AUTOSAR XML (schema 3.1.2)
package /Components/SWC_EBStub
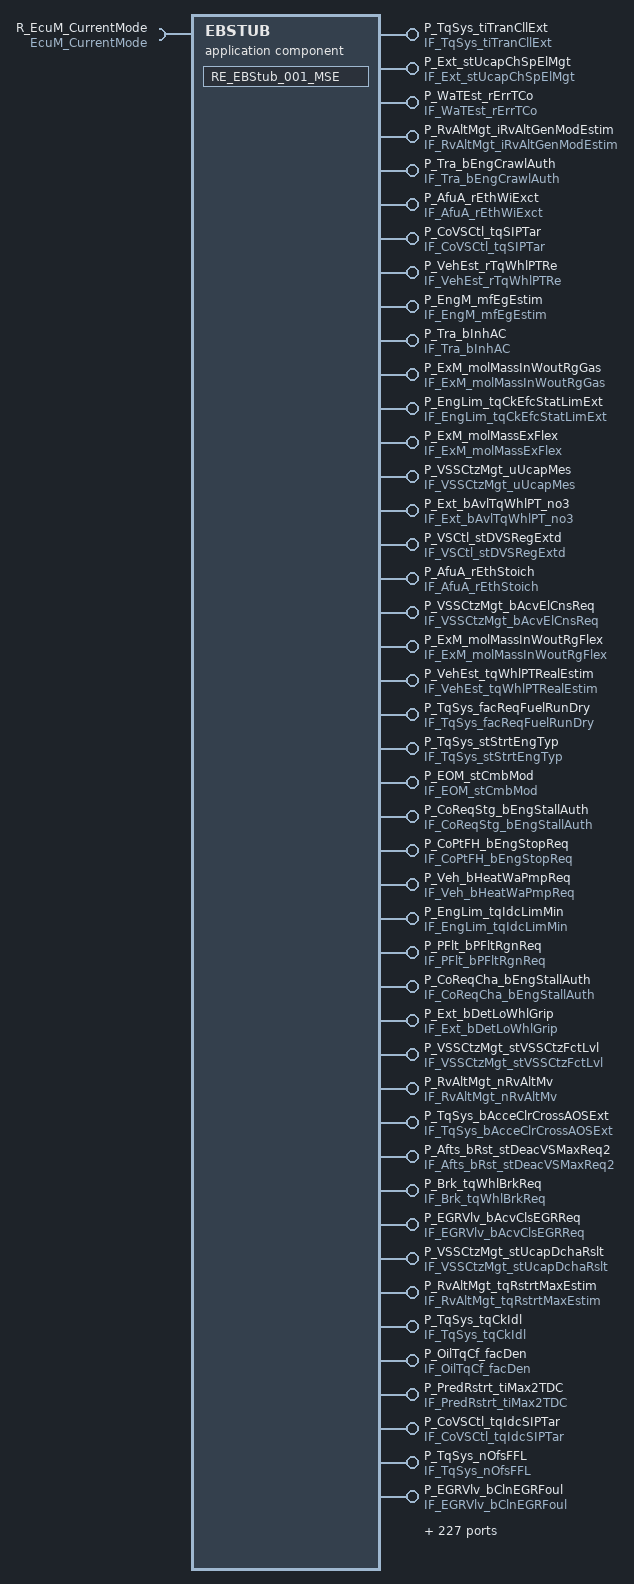
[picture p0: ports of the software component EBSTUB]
  application software component type EBSTUB
    require port R_EcuM_CurrentMode: required-interface=EcuM_CurrentMode
    271 x provide port:
      P_TqSys_tiTranCllExt: unqueued-sender-com-spec{data-element=TqSys_tiTranCllExt, can-invalidate=false, init-value=ConstantValue}, provided-interface=IF_TqSys_tiTranCllExt
      P_Ext_stUcapChSpElMgt: unqueued-sender-com-spec{data-element=Ext_stUcapChSpElMgt, can-invalidate=false, init-value=ConstantValue1}, provided-interface=IF_Ext_stUcapChSpElMgt
      P_WaTEst_rErrTCo: unqueued-sender-com-spec{data-element=WaTEst_rErrTCo, can-invalidate=false, init-value=ConstantValue3}, provided-interface=IF_WaTEst_rErrTCo
      P_RvAltMgt_iRvAltGenModEstim: unqueued-sender-com-spec{data-element=RvAltMgt_iRvAltGenModEstim, can-invalidate=false, init-value=ConstantValue5}, provided-interface=IF_RvAltMgt_iRvAltGenModEstim
      P_Tra_bEngCrawlAuth: unqueued-sender-com-spec{data-element=Tra_bEngCrawlAuth, can-invalidate=false, init-value=ConstantValue7}, provided-interface=IF_Tra_bEngCrawlAuth
      P_AfuA_rEthWiExct: unqueued-sender-com-spec{data-element=AfuA_rEthWiExct, can-invalidate=false, init-value=ConstantValue9}, provided-interface=IF_AfuA_rEthWiExct
      P_CoVSCtl_tqSIPTar: unqueued-sender-com-spec{data-element=CoVSCtl_tqSIPTar, can-invalidate=false, init-value=ConstantValue11}, provided-interface=IF_CoVSCtl_tqSIPTar
      P_VehEst_rTqWhlPTRe: unqueued-sender-com-spec{data-element=VehEst_rTqWhlPTRe, can-invalidate=false, init-value=ConstantValue13}, provided-interface=IF_VehEst_rTqWhlPTRe
      P_EngM_mfEgEstim: unqueued-sender-com-spec{data-element=EngM_mfEgEstim, can-invalidate=false, init-value=ConstantValue15}, provided-interface=IF_EngM_mfEgEstim
      P_Tra_bInhAC: unqueued-sender-com-spec{data-element=Tra_bInhAC, can-invalidate=false, init-value=ConstantValue17}, provided-interface=IF_Tra_bInhAC
      P_ExM_molMassInWoutRgGas: unqueued-sender-com-spec{data-element=ExM_molMassInWoutRgGas, can-invalidate=false, init-value=ConstantValue19}, provided-interface=IF_ExM_molMassInWoutRgGas
      P_EngLim_tqCkEfcStatLimExt: unqueued-sender-com-spec{data-element=EngLim_tqCkEfcStatLimExt, can-invalidate=false, init-value=ConstantValue21}, provided-interface=IF_EngLim_tqCkEfcStatLimExt
      P_ExM_molMassExFlex: unqueued-sender-com-spec{data-element=ExM_molMassExFlex, can-invalidate=false, init-value=ConstantValue23}, provided-interface=IF_ExM_molMassExFlex
      P_VSSCtzMgt_uUcapMes: unqueued-sender-com-spec{data-element=VSSCtzMgt_uUcapMes, can-invalidate=false, init-value=ConstantValue25}, provided-interface=IF_VSSCtzMgt_uUcapMes
      P_Ext_bAvlTqWhlPT_no3: unqueued-sender-com-spec{data-element=Ext_bAvlTqWhlPT_no3, can-invalidate=false, init-value=ConstantValue27}, provided-interface=IF_Ext_bAvlTqWhlPT_no3
      P_VSCtl_stDVSRegExtd: unqueued-sender-com-spec{data-element=VSCtl_stDVSRegExtd, can-invalidate=false, init-value=ConstantValue29}, provided-interface=IF_VSCtl_stDVSRegExtd
      P_AfuA_rEthStoich: unqueued-sender-com-spec{data-element=AfuA_rEthStoich, can-invalidate=false, init-value=ConstantValue31}, provided-interface=IF_AfuA_rEthStoich
      P_VSSCtzMgt_bAcvElCnsReq: unqueued-sender-com-spec{data-element=VSSCtzMgt_bAcvElCnsReq, can-invalidate=false, init-value=ConstantValue33}, provided-interface=IF_VSSCtzMgt_bAcvElCnsReq
      P_ExM_molMassInWoutRgFlex: unqueued-sender-com-spec{data-element=ExM_molMassInWoutRgFlex, can-invalidate=false, init-value=ConstantValue35}, provided-interface=IF_ExM_molMassInWoutRgFlex
      P_VehEst_tqWhlPTRealEstim: unqueued-sender-com-spec{data-element=VehEst_tqWhlPTRealEstim, can-invalidate=false, init-value=ConstantValue37}, provided-interface=IF_VehEst_tqWhlPTRealEstim
      P_TqSys_facReqFuelRunDry: unqueued-sender-com-spec{data-element=TqSys_facReqFuelRunDry, can-invalidate=false, init-value=ConstantValue39}, provided-interface=IF_TqSys_facReqFuelRunDry
      P_TqSys_stStrtEngTyp: unqueued-sender-com-spec{data-element=TqSys_stStrtEngTyp, can-invalidate=false, init-value=ConstantValue41}, provided-interface=IF_TqSys_stStrtEngTyp
      P_EOM_stCmbMod: unqueued-sender-com-spec{data-element=EOM_stCmbMod, can-invalidate=false, init-value=ConstantValue43}, provided-interface=IF_EOM_stCmbMod
      P_CoReqStg_bEngStallAuth: unqueued-sender-com-spec{data-element=CoReqStg_bEngStallAuth, can-invalidate=false, init-value=ConstantValue45}, provided-interface=IF_CoReqStg_bEngStallAuth
      P_CoPtFH_bEngStopReq: unqueued-sender-com-spec{data-element=CoPtFH_bEngStopReq, can-invalidate=false, init-value=ConstantValue47}, provided-interface=IF_CoPtFH_bEngStopReq
      P_Veh_bHeatWaPmpReq: unqueued-sender-com-spec{data-element=Veh_bHeatWaPmpReq, can-invalidate=false, init-value=ConstantValue49}, provided-interface=IF_Veh_bHeatWaPmpReq
      P_EngLim_tqIdcLimMin: unqueued-sender-com-spec{data-element=EngLim_tqIdcLimMin, can-invalidate=false, init-value=ConstantValue51}, provided-interface=IF_EngLim_tqIdcLimMin
      P_PFlt_bPFltRgnReq: unqueued-sender-com-spec{data-element=PFlt_bPFltRgnReq, can-invalidate=false, init-value=ConstantValue53}, provided-interface=IF_PFlt_bPFltRgnReq
      P_CoReqCha_bEngStallAuth: unqueued-sender-com-spec{data-element=CoReqCha_bEngStallAuth, can-invalidate=false, init-value=ConstantValue55}, provided-interface=IF_CoReqCha_bEngStallAuth
      P_Ext_bDetLoWhlGrip: unqueued-sender-com-spec{data-element=Ext_bDetLoWhlGrip, can-invalidate=false, init-value=ConstantValue57}, provided-interface=IF_Ext_bDetLoWhlGrip
      P_VSSCtzMgt_stVSSCtzFctLvl: unqueued-sender-com-spec{data-element=VSSCtzMgt_stVSSCtzFctLvl, can-invalidate=false, init-value=ConstantValue59}, provided-interface=IF_VSSCtzMgt_stVSSCtzFctLvl
      P_RvAltMgt_nRvAltMv: unqueued-sender-com-spec{data-element=RvAltMgt_nRvAltMv, can-invalidate=false, init-value=ConstantValue61}, provided-interface=IF_RvAltMgt_nRvAltMv
      P_TqSys_bAcceClrCrossAOSExt: unqueued-sender-com-spec{data-element=TqSys_bAcceClrCrossAOSExt, can-invalidate=false, init-value=ConstantValue63}, provided-interface=IF_TqSys_bAcceClrCrossAOSExt
      P_Afts_bRst_stDeacVSMaxReq2: unqueued-sender-com-spec{data-element=Afts_bRst_stDeacVSMaxReq2, can-invalidate=false, init-value=ConstantValue65}, provided-interface=IF_Afts_bRst_stDeacVSMaxReq2
      P_Brk_tqWhlBrkReq: unqueued-sender-com-spec{data-element=Brk_tqWhlBrkReq, can-invalidate=false, init-value=ConstantValue67}, provided-interface=IF_Brk_tqWhlBrkReq
      P_EGRVlv_bAcvClsEGRReq: unqueued-sender-com-spec{data-element=EGRVlv_bAcvClsEGRReq, can-invalidate=false, init-value=ConstantValue69}, provided-interface=IF_EGRVlv_bAcvClsEGRReq
      P_VSSCtzMgt_stUcapDchaRslt: unqueued-sender-com-spec{data-element=VSSCtzMgt_stUcapDchaRslt, can-invalidate=false, init-value=ConstantValue71}, provided-interface=IF_VSSCtzMgt_stUcapDchaRslt
      P_RvAltMgt_tqRstrtMaxEstim: unqueued-sender-com-spec{data-element=RvAltMgt_tqRstrtMaxEstim, can-invalidate=false, init-value=ConstantValue73}, provided-interface=IF_RvAltMgt_tqRstrtMaxEstim
      P_TqSys_tqCkIdl: unqueued-sender-com-spec{data-element=TqSys_tqCkIdl, can-invalidate=false, init-value=ConstantValue75}, provided-interface=IF_TqSys_tqCkIdl
      P_OilTqCf_facDen: unqueued-sender-com-spec{data-element=OilTqCf_facDen, can-invalidate=false, init-value=ConstantValue77}, provided-interface=IF_OilTqCf_facDen
      P_PredRstrt_tiMax2TDC: unqueued-sender-com-spec{data-element=PredRstrt_tiMax2TDC, can-invalidate=false, init-value=ConstantValue79}, provided-interface=IF_PredRstrt_tiMax2TDC
      P_CoVSCtl_tqIdcSIPTar: unqueued-sender-com-spec{data-element=CoVSCtl_tqIdcSIPTar, can-invalidate=false, init-value=ConstantValue81}, provided-interface=IF_CoVSCtl_tqIdcSIPTar
      P_TqSys_nOfsFFL: unqueued-sender-com-spec{data-element=TqSys_nOfsFFL, can-invalidate=false, init-value=ConstantValue83}, provided-interface=IF_TqSys_nOfsFFL
      P_EGRVlv_bClnEGRFoul: unqueued-sender-com-spec{data-element=EGRVlv_bClnEGRFoul, can-invalidate=false, init-value=ConstantValue85}, provided-interface=IF_EGRVlv_bClnEGRFoul
      P_TqLimUH_bAcvUnBlsEng: unqueued-sender-com-spec{data-element=TqLimUH_bAcvUnBlsEng, can-invalidate=false, init-value=ConstantValue87}, provided-interface=IF_TqLimUH_bAcvUnBlsEng
      P_PtLim_tqWhlPTMaxCtla: unqueued-sender-com-spec{data-element=PtLim_tqWhlPTMaxCtla, can-invalidate=false, init-value=ConstantValue89}, provided-interface=IF_PtLim_tqWhlPTMaxCtla
      P_TqSys_bIdlAcv: unqueued-sender-com-spec{data-element=TqSys_bIdlAcv, can-invalidate=false, init-value=ConstantValue91}, provided-interface=IF_TqSys_bIdlAcv
      P_ExM_tExFlexOfs: unqueued-sender-com-spec{data-element=ExM_tExFlexOfs, can-invalidate=false, init-value=ConstantValue93}, provided-interface=IF_ExM_tExFlexOfs
      P_CoReqVeh_bEngASERstrtReq: unqueued-sender-com-spec{data-element=CoReqVeh_bEngASERstrtReq, can-invalidate=false, init-value=ConstantValue95}, provided-interface=IF_CoReqVeh_bEngASERstrtReq
      P_TqEst_tqIdcStrt: unqueued-sender-com-spec{data-element=TqEst_tqIdcStrt, can-invalidate=false, init-value=ConstantValue97}, provided-interface=IF_TqEst_tqIdcStrt
      P_ExM_tExGas: unqueued-sender-com-spec{data-element=ExM_tExGas, can-invalidate=false, init-value=ConstantValue99}, provided-interface=IF_ExM_tExGas
      P_CoPt_tqEfcAirCordLimExtTqGBx: unqueued-sender-com-spec{data-element=CoPt_tqEfcAirCordLimExtTqGBx, can-invalidate=false, init-value=ConstantValue101}, provided-interface=IF_CoPt_tqEfcAirCordLimExtTqGBx
      P_TqDem_tqWhlPTPreCoVSCMaxReq: unqueued-sender-com-spec{data-element=TqDem_tqWhlPTPreCoVSCMaxReq, can-invalidate=false, init-value=ConstantValue103}, provided-interface=IF_TqDem_tqWhlPTPreCoVSCMaxReq
      P_Ext_tVSS: unqueued-sender-com-spec{data-element=Ext_tVSS, can-invalidate=false, init-value=ConstantValue105}, provided-interface=IF_Ext_tVSS
      P_EGRVlv_rOp: unqueued-sender-com-spec{data-element=EGRVlv_rOp, can-invalidate=false, init-value=ConstantValue107}, provided-interface=IF_EGRVlv_rOp
      P_CoCha_bInhEGRExt: unqueued-sender-com-spec{data-element=CoCha_bInhEGRExt, can-invalidate=false, init-value=ConstantValue109}, provided-interface=IF_CoCha_bInhEGRExt
      P_RvAltMgt_tRvAltStatEstim: unqueued-sender-com-spec{data-element=RvAltMgt_tRvAltStatEstim, can-invalidate=false, init-value=ConstantValue111}, provided-interface=IF_RvAltMgt_tRvAltStatEstim
      P_EngM_tUsTrbEstimFil: unqueued-sender-com-spec{data-element=EngM_tUsTrbEstimFil, can-invalidate=false, init-value=ConstantValue113}, provided-interface=IF_EngM_tUsTrbEstimFil
      P_Afts_bVSSCtzActrTestCmd: unqueued-sender-com-spec{data-element=Afts_bVSSCtzActrTestCmd, can-invalidate=false, init-value=ConstantValue115}, provided-interface=IF_Afts_bVSSCtzActrTestCmd
      P_Ext_stPwrLimCf: unqueued-sender-com-spec{data-element=Ext_stPwrLimCf, can-invalidate=false, init-value=ConstantValue117}, provided-interface=IF_Ext_stPwrLimCf
      P_ExM_molMassExGas: unqueued-sender-com-spec{data-element=ExM_molMassExGas, can-invalidate=false, init-value=ConstantValue119}, provided-interface=IF_ExM_molMassExGas
      P_TqSys_tqCkEfcAirFilExt: unqueued-sender-com-spec{data-element=TqSys_tqCkEfcAirFilExt, can-invalidate=false, init-value=ConstantValue121}, provided-interface=IF_TqSys_tqCkEfcAirFilExt
      P_Afts_bRstTrbCaseDmgReq: unqueued-sender-com-spec{data-element=Afts_bRstTrbCaseDmgReq, can-invalidate=false, init-value=ConstantValue123}, provided-interface=IF_Afts_bRstTrbCaseDmgReq
      P_SftyMgt_bDeacIrvVSLim: unqueued-sender-com-spec{data-element=SftyMgt_bDeacIrvVSLim, can-invalidate=false, init-value=ConstantValue125}, provided-interface=IF_SftyMgt_bDeacIrvVSLim
      P_IgSys_agIgCmbModOfsMinThermo: unqueued-sender-com-spec{data-element=IgSys_agIgCmbModOfsMinThermo, can-invalidate=false, init-value=ConstantValue127}, provided-interface=IF_IgSys_agIgCmbModOfsMinThermo
      P_PtLim_tqWhlPTMinNotCtla: unqueued-sender-com-spec{data-element=PtLim_tqWhlPTMinNotCtla, can-invalidate=false, init-value=ConstantValue129}, provided-interface=IF_PtLim_tqWhlPTMinNotCtla
      P_Stg_tSysStrWhl: unqueued-sender-com-spec{data-element=Stg_tSysStrWhl, can-invalidate=false, init-value=ConstantValue131}, provided-interface=IF_Stg_tSysStrWhl
      P_CoEmSTT_bEngASERstrtReq: unqueued-sender-com-spec{data-element=CoEmSTT_bEngASERstrtReq, can-invalidate=false, init-value=ConstantValue133}, provided-interface=IF_CoEmSTT_bEngASERstrtReq
      P_GlwCtl_bEngRunAuth: unqueued-sender-com-spec{data-element=GlwCtl_bEngRunAuth, can-invalidate=false, init-value=ConstantValue135}, provided-interface=IF_GlwCtl_bEngRunAuth
      P_CoPtUH_bEngAsiReqExt: unqueued-sender-com-spec{data-element=CoPtUH_bEngAsiReqExt, can-invalidate=false, init-value=ConstantValue137}, provided-interface=IF_CoPtUH_bEngAsiReqExt
      P_ExM_prm_facFlex: unqueued-sender-com-spec{data-element=ExM_prm_facFlex, can-invalidate=false, init-value=ArrayConstantValue}, provided-interface=IF_ExM_prm_facFlex
      P_CoEmSTT_bAuthBoost: unqueued-sender-com-spec{data-element=CoEmSTT_bAuthBoost, can-invalidate=false, init-value=ConstantValue139}, provided-interface=IF_CoEmSTT_bAuthBoost
      P_ExM_prm_facGas: unqueued-sender-com-spec{data-element=ExM_prm_facGas, can-invalidate=false, init-value=ArrayConstantValue141}, provided-interface=IF_ExM_prm_facGas
      P_Afts_bRstCylHdDmgReq: unqueued-sender-com-spec{data-element=Afts_bRstCylHdDmgReq, can-invalidate=false, init-value=ConstantValue143}, provided-interface=IF_Afts_bRstCylHdDmgReq
      P_ExM_cppExFlex: unqueued-sender-com-spec{data-element=ExM_cppExFlex, can-invalidate=false, init-value=ConstantValue145}, provided-interface=IF_ExM_cppExFlex
      P_VSCtl_stVSReg: unqueued-sender-com-spec{data-element=VSCtl_stVSReg, can-invalidate=false, init-value=ConstantValue147}, provided-interface=IF_VSCtl_stVSReg
      P_CoSync_bAgEsCfm: unqueued-sender-com-spec{data-element=CoSync_bAgEsCfm, can-invalidate=false, init-value=ConstantValue149}, provided-interface=IF_CoSync_bAgEsCfm
      P_RvAltMgt_bStopStrtWarn: unqueued-sender-com-spec{data-element=RvAltMgt_bStopStrtWarn, can-invalidate=false, init-value=ConstantValue151}, provided-interface=IF_RvAltMgt_bStopStrtWarn
      P_EOM_idxBas2InjCur: unqueued-sender-com-spec{data-element=EOM_idxBas2InjCur, can-invalidate=false, init-value=ConstantValue153}, provided-interface=IF_EOM_idxBas2InjCur
      P_TqSys_noCylCutAuthExt: unqueued-sender-com-spec{data-element=TqSys_noCylCutAuthExt, can-invalidate=false, init-value=ConstantValue155}, provided-interface=IF_TqSys_noCylCutAuthExt
      P_CoReqDmpr_stEngStopAuth: unqueued-sender-com-spec{data-element=CoReqDmpr_stEngStopAuth, can-invalidate=false, init-value=ConstantValue157}, provided-interface=IF_CoReqDmpr_stEngStopAuth
      P_VSCtl_stVSLim: unqueued-sender-com-spec{data-element=VSCtl_stVSLim, can-invalidate=false, init-value=ConstantValue159}, provided-interface=IF_VSCtl_stVSLim
      P_VehEst_bORng_nPT: unqueued-sender-com-spec{data-element=VehEst_bORng_nPT, can-invalidate=false, init-value=ConstantValue161}, provided-interface=IF_VehEst_bORng_nPT
      P_IgSys_agIgOptmFlex: unqueued-sender-com-spec{data-element=IgSys_agIgOptmFlex, can-invalidate=false, init-value=ConstantValue163}, provided-interface=IF_IgSys_agIgOptmFlex
      P_Afts_bRst_stDeacVSLimReq2: unqueued-sender-com-spec{data-element=Afts_bRst_stDeacVSLimReq2, can-invalidate=false, init-value=ConstantValue165}, provided-interface=IF_Afts_bRst_stDeacVSLimReq2
      P_Ext_bAvlTqWhlPT_no2: unqueued-sender-com-spec{data-element=Ext_bAvlTqWhlPT_no2, can-invalidate=false, init-value=ConstantValue167}, provided-interface=IF_Ext_bAvlTqWhlPT_no2
      P_CoPtFH_stPwt: unqueued-sender-com-spec{data-element=CoPtFH_stPwt, can-invalidate=false, init-value=ConstantValue169}, provided-interface=IF_CoPtFH_stPwt
      P_TqSys_bInhBrio: unqueued-sender-com-spec{data-element=TqSys_bInhBrio, can-invalidate=false, init-value=ConstantValue171}, provided-interface=IF_TqSys_bInhBrio
      P_AfuA_rEthWoutExct: unqueued-sender-com-spec{data-element=AfuA_rEthWoutExct, can-invalidate=false, init-value=ConstantValue173}, provided-interface=IF_AfuA_rEthWoutExct
      P_ExM_facIgCorGas: unqueued-sender-com-spec{data-element=ExM_facIgCorGas, can-invalidate=false, init-value=ConstantValue175}, provided-interface=IF_ExM_facIgCorGas
      P_Ext_bAvlTqWhlPT_no1: unqueued-sender-com-spec{data-element=Ext_bAvlTqWhlPT_no1, can-invalidate=false, init-value=ConstantValue177}, provided-interface=IF_Ext_bAvlTqWhlPT_no1
      P_Afts_bRst_stDeacVSRegReq2: unqueued-sender-com-spec{data-element=Afts_bRst_stDeacVSRegReq2, can-invalidate=false, init-value=ConstantValue179}, provided-interface=IF_Afts_bRst_stDeacVSRegReq2
      P_CoPt_nTarIdlCVC: unqueued-sender-com-spec{data-element=CoPt_nTarIdlCVC, can-invalidate=false, init-value=ConstantValue181}, provided-interface=IF_CoPt_nTarIdlCVC
      P_EngReqH_bEngStallAuth: unqueued-sender-com-spec{data-element=EngReqH_bEngStallAuth, can-invalidate=false, init-value=ConstantValue183}, provided-interface=IF_EngReqH_bEngStallAuth
      P_TqCmp_bOpFSFReq_tAir: unqueued-sender-com-spec{data-element=TqCmp_bOpFSFReq_tAir, can-invalidate=false, init-value=ConstantValue185}, provided-interface=IF_TqCmp_bOpFSFReq_tAir
      P_IgSys_agIgMinThermoGas: unqueued-sender-com-spec{data-element=IgSys_agIgMinThermoGas, can-invalidate=false, init-value=ConstantValue187}, provided-interface=IF_IgSys_agIgMinThermoGas
      P_TqSys_bDeceDetAOSExt: unqueued-sender-com-spec{data-element=TqSys_bDeceDetAOSExt, can-invalidate=false, init-value=ConstantValue189}, provided-interface=IF_TqSys_bDeceDetAOSExt
      P_TqSys_nOfsLauchIdlTakeOff: unqueued-sender-com-spec{data-element=TqSys_nOfsLauchIdlTakeOff, can-invalidate=false, init-value=ConstantValue191}, provided-interface=IF_TqSys_nOfsLauchIdlTakeOff
      P_Brk_bBrkAuto: unqueued-sender-com-spec{data-element=Brk_bBrkAuto, can-invalidate=false, init-value=ConstantValue193}, provided-interface=IF_Brk_bBrkAuto
      P_Ext_bEspVehVld: unqueued-sender-com-spec{data-element=Ext_bEspVehVld, can-invalidate=false, init-value=ConstantValue195}, provided-interface=IF_Ext_bEspVehVld
      P_FARSp_rDeltaMixtStiTWCSp: unqueued-sender-com-spec{data-element=FARSp_rDeltaMixtStiTWCSp, can-invalidate=false, init-value=ConstantValue197}, provided-interface=IF_FARSp_rDeltaMixtStiTWCSp
      P_RvAltMgt_uRvAltMes: unqueued-sender-com-spec{data-element=RvAltMgt_uRvAltMes, can-invalidate=false, init-value=ConstantValue199}, provided-interface=IF_RvAltMgt_uRvAltMes
      P_CoReqDamp_bEngStallAuth: unqueued-sender-com-spec{data-element=CoReqDamp_bEngStallAuth, can-invalidate=false, init-value=ConstantValue201}, provided-interface=IF_CoReqDamp_bEngStallAuth
      P_ElSysCo_rSpdFanReq: unqueued-sender-com-spec{data-element=ElSysCo_rSpdFanReq, can-invalidate=false, init-value=ConstantValue203}, provided-interface=IF_ElSysCo_rSpdFanReq
      P_CoPt_bDeacCllExt: unqueued-sender-com-spec{data-element=CoPt_bDeacCllExt, can-invalidate=false, init-value=ConstantValue205}, provided-interface=IF_CoPt_bDeacCllExt
      P_CoVlv_rOpRadCoVlvMes: unqueued-sender-com-spec{data-element=CoVlv_rOpRadCoVlvMes, can-invalidate=false, init-value=ConstantValue207}, provided-interface=IF_CoVlv_rOpRadCoVlvMes
      P_EOM_stEngModReq: unqueued-sender-com-spec{data-element=EOM_stEngModReq, can-invalidate=false, init-value=ConstantValue209}, provided-interface=IF_EOM_stEngModReq
      P_CoCha_tqEfcAirReqExt: unqueued-sender-com-spec{data-element=CoCha_tqEfcAirReqExt, can-invalidate=false, init-value=ConstantValue211}, provided-interface=IF_CoCha_tqEfcAirReqExt
      P_Tra_stVehDirEstim: unqueued-sender-com-spec{data-element=Tra_stVehDirEstim, can-invalidate=false, init-value=ConstantValue213}, provided-interface=IF_Tra_stVehDirEstim
      P_RvAltMgt_stRvAltRstrtFbCmd: unqueued-sender-com-spec{data-element=RvAltMgt_stRvAltRstrtFbCmd, can-invalidate=false, init-value=ConstantValue215}, provided-interface=IF_RvAltMgt_stRvAltRstrtFbCmd
      P_Ext_bAvrFrntWhlVld: unqueued-sender-com-spec{data-element=Ext_bAvrFrntWhlVld, can-invalidate=false, init-value=ConstantValue217}, provided-interface=IF_Ext_bAvrFrntWhlVld
      P_EngLim_tqIdcSmkLim: unqueued-sender-com-spec{data-element=EngLim_tqIdcSmkLim, can-invalidate=false, init-value=ConstantValue219}, provided-interface=IF_EngLim_tqIdcSmkLim
      P_OilTqCf_bPresOilReqCf: unqueued-sender-com-spec{data-element=OilTqCf_bPresOilReqCf, can-invalidate=false, init-value=ConstantValue221}, provided-interface=IF_OilTqCf_bPresOilReqCf
      P_Afts_bUcapChgIdc: unqueued-sender-com-spec{data-element=Afts_bUcapChgIdc, can-invalidate=false, init-value=ConstantValue223}, provided-interface=IF_Afts_bUcapChgIdc
      P_Ext_bFrntLeftWhlVehVld: unqueued-sender-com-spec{data-element=Ext_bFrntLeftWhlVehVld, can-invalidate=false, init-value=ConstantValue225}, provided-interface=IF_Ext_bFrntLeftWhlVehVld
      P_EngM_dstInVlvClrCor: unqueued-sender-com-spec{data-element=EngM_dstInVlvClrCor, can-invalidate=false, init-value=ConstantValue227}, provided-interface=IF_EngM_dstInVlvClrCor
      P_Afts_bRstExMnfDmgReq: unqueued-sender-com-spec{data-element=Afts_bRstExMnfDmgReq, can-invalidate=false, init-value=ConstantValue229}, provided-interface=IF_Afts_bRstExMnfDmgReq
      P_EngM_facCorOfsEfc: unqueued-sender-com-spec{data-element=EngM_facCorOfsEfc, can-invalidate=false, init-value=ConstantValue231}, provided-interface=IF_EngM_facCorOfsEfc
      P_Tra_bSpdVehLoDet: unqueued-sender-com-spec{data-element=Tra_bSpdVehLoDet, can-invalidate=false, init-value=ConstantValue233}, provided-interface=IF_Tra_bSpdVehLoDet
      P_IgSys_prm_facFlex: unqueued-sender-com-spec{data-element=IgSys_prm_facFlex, can-invalidate=false, init-value=ArrayConstantValue235}, provided-interface=IF_IgSys_prm_facFlex
      P_EOM_idxBas1InjCur: unqueued-sender-com-spec{data-element=EOM_idxBas1InjCur, can-invalidate=false, init-value=ConstantValue237}, provided-interface=IF_EOM_idxBas1InjCur
      P_InjSP_mfFuPoI1Req: unqueued-sender-com-spec{data-element=InjSP_mfFuPoI1Req, can-invalidate=false, init-value=ConstantValue239}, provided-interface=IF_InjSP_mfFuPoI1Req
      P_Ext_bTqAltEstimElSys: unqueued-sender-com-spec{data-element=Ext_bTqAltEstimElSys, can-invalidate=false, init-value=ConstantValue241}, provided-interface=IF_Ext_bTqAltEstimElSys
      P_CoPt_bAcvTqNCordBuf: unqueued-sender-com-spec{data-element=CoPt_bAcvTqNCordBuf, can-invalidate=false, init-value=ConstantValue243}, provided-interface=IF_CoPt_bAcvTqNCordBuf
      P_Ext_stSpdFanPFltReq: unqueued-sender-com-spec{data-element=Ext_stSpdFanPFltReq, can-invalidate=false, init-value=ConstantValue245}, provided-interface=IF_Ext_stSpdFanPFltReq
      P_VehEst_bCtlTqWhlPT: unqueued-sender-com-spec{data-element=VehEst_bCtlTqWhlPT, can-invalidate=false, init-value=ConstantValue247}, provided-interface=IF_VehEst_bCtlTqWhlPT
      P_IgSys_rTarStatIgSpEff: unqueued-sender-com-spec{data-element=IgSys_rTarStatIgSpEff, can-invalidate=false, init-value=ConstantValue249}, provided-interface=IF_IgSys_rTarStatIgSpEff
      P_EngLim_tqIdcEngLim: unqueued-sender-com-spec{data-element=EngLim_tqIdcEngLim, can-invalidate=false, init-value=ConstantValue251}, provided-interface=IF_EngLim_tqIdcEngLim
      P_TqSys_tqCkEfcFilExt: unqueued-sender-com-spec{data-element=TqSys_tqCkEfcFilExt, can-invalidate=false, init-value=ConstantValue253}, provided-interface=IF_TqSys_tqCkEfcFilExt
      P_PARM_bEngRstrtAutnAvl: unqueued-sender-com-spec{data-element=PARM_bEngRstrtAutnAvl, can-invalidate=false, init-value=ConstantValue255}, provided-interface=IF_PARM_bEngRstrtAutnAvl
      P_TqSys_stDrivFilPhaExt: unqueued-sender-com-spec{data-element=TqSys_stDrivFilPhaExt, can-invalidate=false, init-value=ConstantValue257}, provided-interface=IF_TqSys_stDrivFilPhaExt
      P_EGRVlv_rOpEGRReq: unqueued-sender-com-spec{data-element=EGRVlv_rOpEGRReq, can-invalidate=false, init-value=ConstantValue259}, provided-interface=IF_EGRVlv_rOpEGRReq
      P_VSSCtzMgt_tUcapMes: unqueued-sender-com-spec{data-element=VSSCtzMgt_tUcapMes, can-invalidate=false, init-value=ConstantValue261}, provided-interface=IF_VSSCtzMgt_tUcapMes
      P_VSCtl_rCtlTqWhlPTPotDVSReg: unqueued-sender-com-spec{data-element=VSCtl_rCtlTqWhlPTPotDVSReg, can-invalidate=false, init-value=ConstantValue263}, provided-interface=IF_VSCtl_rCtlTqWhlPTPotDVSReg
      P_Ext_bDiDrivFilReq: unqueued-sender-com-spec{data-element=Ext_bDiDrivFilReq, can-invalidate=false, init-value=ConstantValue265}, provided-interface=IF_Ext_bDiDrivFilReq
      P_VSCtl_tiCfmSdwnDVSRegReq: unqueued-sender-com-spec{data-element=VSCtl_tiCfmSdwnDVSRegReq, can-invalidate=false, init-value=ConstantValue267}, provided-interface=IF_VSCtl_tiCfmSdwnDVSRegReq
      P_CoReqVeh_bEngStallAuth: unqueued-sender-com-spec{data-element=CoReqVeh_bEngStallAuth, can-invalidate=false, init-value=ConstantValue269}, provided-interface=IF_CoReqVeh_bEngStallAuth
      P_Blby_bIncIdlSpd: unqueued-sender-com-spec{data-element=Blby_bIncIdlSpd, can-invalidate=false, init-value=ConstantValue271}, provided-interface=IF_Blby_bIncIdlSpd
      P_CoVlv_rOpHeatCoVlvMes: unqueued-sender-com-spec{data-element=CoVlv_rOpHeatCoVlvMes, can-invalidate=false, init-value=ConstantValue273}, provided-interface=IF_CoVlv_rOpHeatCoVlvMes
      P_CoReqDmpr_bEngRStrtReq: unqueued-sender-com-spec{data-element=CoReqDmpr_bEngRStrtReq, can-invalidate=false, init-value=ConstantValue275}, provided-interface=IF_CoReqDmpr_bEngRStrtReq
      P_TqSys_nTarDynIdl: unqueued-sender-com-spec{data-element=TqSys_nTarDynIdl, can-invalidate=false, init-value=ConstantValue277}, provided-interface=IF_TqSys_nTarDynIdl
      P_Ext_bGslEngPrepReq: unqueued-sender-com-spec{data-element=Ext_bGslEngPrepReq, can-invalidate=false, init-value=ConstantValue279}, provided-interface=IF_Ext_bGslEngPrepReq
      P_EGRVlv_stEGRMod: unqueued-sender-com-spec{data-element=EGRVlv_stEGRMod, can-invalidate=false, init-value=ConstantValue281}, provided-interface=IF_EGRVlv_stEGRMod
      P_TqSys_bInhTqDemSptMod: unqueued-sender-com-spec{data-element=TqSys_bInhTqDemSptMod, can-invalidate=false, init-value=ConstantValue283}, provided-interface=IF_TqSys_bInhTqDemSptMod
      P_VSSCtzMgt_stVSSCtzAcvSt: unqueued-sender-com-spec{data-element=VSSCtzMgt_stVSSCtzAcvSt, can-invalidate=false, init-value=ConstantValue285}, provided-interface=IF_VSSCtzMgt_stVSSCtzAcvSt
      P_Ext_bRawMainWaPmpSt: unqueued-sender-com-spec{data-element=Ext_bRawMainWaPmpSt, can-invalidate=false, init-value=ConstantValue287}, provided-interface=IF_Ext_bRawMainWaPmpSt
      P_VehEst_tqWhlPTReq: unqueued-sender-com-spec{data-element=VehEst_tqWhlPTReq, can-invalidate=false, init-value=ConstantValue289}, provided-interface=IF_VehEst_tqWhlPTReq
      P_Afts_bSpcFactOnDeacInh: unqueued-sender-com-spec{data-element=Afts_bSpcFactOnDeacInh, can-invalidate=false, init-value=ConstantValue291}, provided-interface=IF_Afts_bSpcFactOnDeacInh
      P_PtLim_tqWhlPTMaxNotCtla: unqueued-sender-com-spec{data-element=PtLim_tqWhlPTMaxNotCtla, can-invalidate=false, init-value=ConstantValue293}, provided-interface=IF_PtLim_tqWhlPTMaxNotCtla
      P_TqDem_tqWhlPTPreCoVSCMinReq: unqueued-sender-com-spec{data-element=TqDem_tqWhlPTPreCoVSCMinReq, can-invalidate=false, init-value=ConstantValue295}, provided-interface=IF_TqDem_tqWhlPTPreCoVSCMinReq
      P_CoReqCha_bEngASERstrtReq: unqueued-sender-com-spec{data-element=CoReqCha_bEngASERstrtReq, can-invalidate=false, init-value=ConstantValue297}, provided-interface=IF_CoReqCha_bEngASERstrtReq
      P_ExM_cppIngFlex: unqueued-sender-com-spec{data-element=ExM_cppIngFlex, can-invalidate=false, init-value=ConstantValue299}, provided-interface=IF_ExM_cppIngFlex
      P_TqSys_tqAOSCVC: unqueued-sender-com-spec{data-element=TqSys_tqAOSCVC, can-invalidate=false, init-value=ConstantValue301}, provided-interface=IF_TqSys_tqAOSCVC
      P_TqSys_bDeceAcvExt: unqueued-sender-com-spec{data-element=TqSys_bDeceAcvExt, can-invalidate=false, init-value=ConstantValue303}, provided-interface=IF_TqSys_bDeceAcvExt
      P_Blby_mfFuStmCmpAirSys: unqueued-sender-com-spec{data-element=Blby_mfFuStmCmpAirSys, can-invalidate=false, init-value=ConstantValue305}, provided-interface=IF_Blby_mfFuStmCmpAirSys
      P_ExM_facLamCorFlex: unqueued-sender-com-spec{data-element=ExM_facLamCorFlex, can-invalidate=false, init-value=ConstantValue307}, provided-interface=IF_ExM_facLamCorFlex
      P_IgSys_agIgMinCmbGas: unqueued-sender-com-spec{data-element=IgSys_agIgMinCmbGas, can-invalidate=false, init-value=ConstantValue309}, provided-interface=IF_IgSys_agIgMinCmbGas
      P_MCT_tqFrntMchEstim: unqueued-sender-com-spec{data-element=MCT_tqFrntMchEstim, can-invalidate=false, init-value=ConstantValue311}, provided-interface=IF_MCT_tqFrntMchEstim
      P_CoPtFH_bEngRunReq: unqueued-sender-com-spec{data-element=CoPtFH_bEngRunReq, can-invalidate=false, init-value=ConstantValue313}, provided-interface=IF_CoPtFH_bEngRunReq
      P_Afts_bRst_stDeacVSMaxReq1: unqueued-sender-com-spec{data-element=Afts_bRst_stDeacVSMaxReq1, can-invalidate=false, init-value=ConstantValue315}, provided-interface=IF_Afts_bRst_stDeacVSMaxReq1
      P_EngM_facCorSlopEfc: unqueued-sender-com-spec{data-element=EngM_facCorSlopEfc, can-invalidate=false, init-value=ConstantValue317}, provided-interface=IF_EngM_facCorSlopEfc
      P_CoPt_facAntiJerkExt: unqueued-sender-com-spec{data-element=CoPt_facAntiJerkExt, can-invalidate=false, init-value=ConstantValue319}, provided-interface=IF_CoPt_facAntiJerkExt
      P_TqDem_tqWhlPTDrvMinReqRaw: unqueued-sender-com-spec{data-element=TqDem_tqWhlPTDrvMinReqRaw, can-invalidate=false, init-value=ConstantValue321}, provided-interface=IF_TqDem_tqWhlPTDrvMinReqRaw
      P_CoPtASE_bEngStrtTypASEReq: unqueued-sender-com-spec{data-element=CoPtASE_bEngStrtTypASEReq, can-invalidate=false, init-value=ConstantValue323}, provided-interface=IF_CoPtASE_bEngStrtTypASEReq
      P_OilTqCf_facNum: unqueued-sender-com-spec{data-element=OilTqCf_facNum, can-invalidate=false, init-value=ConstantValue325}, provided-interface=IF_OilTqCf_facNum
      P_CoVSCtl_rAccPEngExt: unqueued-sender-com-spec{data-element=CoVSCtl_rAccPEngExt, can-invalidate=false, init-value=ConstantValue327}, provided-interface=IF_CoVSCtl_rAccPEngExt
      P_VehEst_spdVehCrit: unqueued-sender-com-spec{data-element=VehEst_spdVehCrit, can-invalidate=false, init-value=ConstantValue329}, provided-interface=IF_VehEst_spdVehCrit
      P_Afts_bRst_stDeacVSLimReq1: unqueued-sender-com-spec{data-element=Afts_bRst_stDeacVSLimReq1, can-invalidate=false, init-value=ConstantValue331}, provided-interface=IF_Afts_bRst_stDeacVSLimReq1
      P_Ext_rCorSoCHyb: unqueued-sender-com-spec{data-element=Ext_rCorSoCHyb, can-invalidate=false, init-value=ConstantValue333}, provided-interface=IF_Ext_rCorSoCHyb
      P_Ext_bFrntRightWhlVehVld: unqueued-sender-com-spec{data-element=Ext_bFrntRightWhlVehVld, can-invalidate=false, init-value=ConstantValue335}, provided-interface=IF_Ext_bFrntRightWhlVehVld
      P_VSSCtzMgt_rUcapSoHTreat: unqueued-sender-com-spec{data-element=VSSCtzMgt_rUcapSoHTreat, can-invalidate=false, init-value=ConstantValue337}, provided-interface=IF_VSSCtzMgt_rUcapSoHTreat
      P_GlwCtl_bEngRunReq: unqueued-sender-com-spec{data-element=GlwCtl_bEngRunReq, can-invalidate=false, init-value=ConstantValue339}, provided-interface=IF_GlwCtl_bEngRunReq
      P_TqLimEM_tqLimEMExt: unqueued-sender-com-spec{data-element=TqLimEM_tqLimEMExt, can-invalidate=false, init-value=ConstantValue341}, provided-interface=IF_TqLimEM_tqLimEMExt
      P_TqSys_tqCkIdlMin: unqueued-sender-com-spec{data-element=TqSys_tqCkIdlMin, can-invalidate=false, init-value=ConstantValue343}, provided-interface=IF_TqSys_tqCkIdlMin
      P_PFlt_bPFltRgnSrvReq: unqueued-sender-com-spec{data-element=PFlt_bPFltRgnSrvReq, can-invalidate=false, init-value=ConstantValue345}, provided-interface=IF_PFlt_bPFltRgnSrvReq
      P_Ext_bTyreWarn: unqueued-sender-com-spec{data-element=Ext_bTyreWarn, can-invalidate=false, init-value=ConstantValue347}, provided-interface=IF_Ext_bTyreWarn
      P_Blby_bDecPfu: unqueued-sender-com-spec{data-element=Blby_bDecPfu, can-invalidate=false, init-value=ConstantValue349}, provided-interface=IF_Blby_bDecPfu
      P_EngLim_tqIdcEngProt: unqueued-sender-com-spec{data-element=EngLim_tqIdcEngProt, can-invalidate=false, init-value=ConstantValue351}, provided-interface=IF_EngLim_tqIdcEngProt
      P_RvAltMgt_bIdcVldCurGenMod: unqueued-sender-com-spec{data-element=RvAltMgt_bIdcVldCurGenMod, can-invalidate=false, init-value=ConstantValue353}, provided-interface=IF_RvAltMgt_bIdcVldCurGenMod
      P_ExM_tExFlex: unqueued-sender-com-spec{data-element=ExM_tExFlex, can-invalidate=false, init-value=ConstantValue355}, provided-interface=IF_ExM_tExFlex
      P_ExM_facIgCorFlex: unqueued-sender-com-spec{data-element=ExM_facIgCorFlex, can-invalidate=false, init-value=ConstantValue357}, provided-interface=IF_ExM_facIgCorFlex
      P_VSCtl_aVehPotDVSRegReq: unqueued-sender-com-spec{data-element=VSCtl_aVehPotDVSRegReq, can-invalidate=false, init-value=ConstantValue359}, provided-interface=IF_VSCtl_aVehPotDVSRegReq
      P_TqCmp_pwrACAuxLoss: unqueued-sender-com-spec{data-element=TqCmp_pwrACAuxLoss, can-invalidate=false, init-value=ConstantValue361}, provided-interface=IF_TqCmp_pwrACAuxLoss
      P_TqSys_tqIncCllExt: unqueued-sender-com-spec{data-element=TqSys_tqIncCllExt, can-invalidate=false, init-value=ConstantValue363}, provided-interface=IF_TqSys_tqIncCllExt
      P_VSCtl_stCtl_aVehDVSReg: unqueued-sender-com-spec{data-element=VSCtl_stCtl_aVehDVSReg, can-invalidate=false, init-value=ConstantValue365}, provided-interface=IF_VSCtl_stCtl_aVehDVSReg
      P_Afts_bRst_stDeacVSRegReq1: unqueued-sender-com-spec{data-element=Afts_bRst_stDeacVSRegReq1, can-invalidate=false, init-value=ConstantValue367}, provided-interface=IF_Afts_bRst_stDeacVSRegReq1
      P_EngLim_tqIdcSfty: unqueued-sender-com-spec{data-element=EngLim_tqIdcSfty, can-invalidate=false, init-value=ConstantValue369}, provided-interface=IF_EngLim_tqIdcSfty
      P_IgSys_agIgMaxGas: unqueued-sender-com-spec{data-element=IgSys_agIgMaxGas, can-invalidate=false, init-value=ConstantValue371}, provided-interface=IF_IgSys_agIgMaxGas
      P_Brk_tqWhlBrkEstim: unqueued-sender-com-spec{data-element=Brk_tqWhlBrkEstim, can-invalidate=false, init-value=ConstantValue373}, provided-interface=IF_Brk_tqWhlBrkEstim
      P_Tra_bVoltAltBoostReqGBx: unqueued-sender-com-spec{data-element=Tra_bVoltAltBoostReqGBx, can-invalidate=false, init-value=ConstantValue375}, provided-interface=IF_Tra_bVoltAltBoostReqGBx
      P_WaTEst_tMtlEngEstim: unqueued-sender-com-spec{data-element=WaTEst_tMtlEngEstim, can-invalidate=false, init-value=ConstantValue377}, provided-interface=IF_WaTEst_tMtlEngEstim
      P_Afts_bRstCylBlockDmgReq: unqueued-sender-com-spec{data-element=Afts_bRstCylBlockDmgReq, can-invalidate=false, init-value=ConstantValue379}, provided-interface=IF_Afts_bRstCylBlockDmgReq
      P_TqSys_tqThdPha3Ext: unqueued-sender-com-spec{data-element=TqSys_tqThdPha3Ext, can-invalidate=false, init-value=ConstantValue381}, provided-interface=IF_TqSys_tqThdPha3Ext
      P_ExM_pMes: unqueued-sender-com-spec{data-element=ExM_pMes, can-invalidate=false, init-value=ConstantValue383}, provided-interface=IF_ExM_pMes
      P_PtLim_tqWhlThPTPotMin: unqueued-sender-com-spec{data-element=PtLim_tqWhlThPTPotMin, can-invalidate=false, init-value=ConstantValue385}, provided-interface=IF_PtLim_tqWhlThPTPotMin
      P_TqSys_tqCkIdlMax: unqueued-sender-com-spec{data-element=TqSys_tqCkIdlMax, can-invalidate=false, init-value=ConstantValue387}, provided-interface=IF_TqSys_tqCkIdlMax
      P_PtLim_tqWhlPTPotMinCtla: unqueued-sender-com-spec{data-element=PtLim_tqWhlPTPotMinCtla, can-invalidate=false, init-value=ConstantValue389}, provided-interface=IF_PtLim_tqWhlPTPotMinCtla
      P_IgSys_agIgMinCmbFlex: unqueued-sender-com-spec{data-element=IgSys_agIgMinCmbFlex, can-invalidate=false, init-value=ConstantValue391}, provided-interface=IF_IgSys_agIgMinCmbFlex
      P_PtLim_tqWhlPTPotMaxCtla_no1: unqueued-sender-com-spec{data-element=PtLim_tqWhlPTPotMaxCtla_no1, can-invalidate=false, init-value=ConstantValue393}, provided-interface=IF_PtLim_tqWhlPTPotMaxCtla_no1
      P_PtLim_tqWhlPTPotMaxCtla_no2: unqueued-sender-com-spec{data-element=PtLim_tqWhlPTPotMaxCtla_no2, can-invalidate=false, init-value=ConstantValue395}, provided-interface=IF_PtLim_tqWhlPTPotMaxCtla_no2
      P_ElSysCo_bOpFSFReq: unqueued-sender-com-spec{data-element=ElSysCo_bOpFSFReq, can-invalidate=false, init-value=ConstantValue397}, provided-interface=IF_ElSysCo_bOpFSFReq
      P_RvAltMgt_tqRvAltGenModEstim: unqueued-sender-com-spec{data-element=RvAltMgt_tqRvAltGenModEstim, can-invalidate=false, init-value=ConstantValue399}, provided-interface=IF_RvAltMgt_tqRvAltGenModEstim
      P_TqAdp_bFrzAdpACAuxOn: unqueued-sender-com-spec{data-element=TqAdp_bFrzAdpACAuxOn, can-invalidate=false, init-value=ConstantValue401}, provided-interface=IF_TqAdp_bFrzAdpACAuxOn
      P_ExM_cppExGas: unqueued-sender-com-spec{data-element=ExM_cppExGas, can-invalidate=false, init-value=ConstantValue403}, provided-interface=IF_ExM_cppExGas
      P_VSSCtzMgt_resVSSCtzEstim: unqueued-sender-com-spec{data-element=VSSCtzMgt_resVSSCtzEstim, can-invalidate=false, init-value=ConstantValue405}, provided-interface=IF_VSSCtzMgt_resVSSCtzEstim
      P_AfuA_rFlex: unqueued-sender-com-spec{data-element=AfuA_rFlex, can-invalidate=false, init-value=ConstantValue407}, provided-interface=IF_AfuA_rFlex
      P_IgSys_agIgMaxFlex: unqueued-sender-com-spec{data-element=IgSys_agIgMaxFlex, can-invalidate=false, init-value=ConstantValue409}, provided-interface=IF_IgSys_agIgMaxFlex
      P_ExM_facLamCorGas: unqueued-sender-com-spec{data-element=ExM_facLamCorGas, can-invalidate=false, init-value=ConstantValue411}, provided-interface=IF_ExM_facLamCorGas
      P_TqSys_tqCkDeceIniExt: unqueued-sender-com-spec{data-element=TqSys_tqCkDeceIniExt, can-invalidate=false, init-value=ConstantValue413}, provided-interface=IF_TqSys_tqCkDeceIniExt
      P_TqCha_tqAirTqDecReqExt: unqueued-sender-com-spec{data-element=TqCha_tqAirTqDecReqExt, can-invalidate=false, init-value=ConstantValue415}, provided-interface=IF_TqCha_tqAirTqDecReqExt
      P_AirSys_rOpEGRCoBypReq: unqueued-sender-com-spec{data-element=AirSys_rOpEGRCoBypReq, can-invalidate=false, init-value=ConstantValue417}, provided-interface=IF_AirSys_rOpEGRCoBypReq
      P_Ext_tECTSp: unqueued-sender-com-spec{data-element=Ext_tECTSp, can-invalidate=false, init-value=ConstantValue419}, provided-interface=IF_Ext_tECTSp
      P_VSCtl_aVehDVSRegReq: unqueued-sender-com-spec{data-element=VSCtl_aVehDVSRegReq, can-invalidate=false, init-value=ConstantValue421}, provided-interface=IF_VSCtl_aVehDVSRegReq
      P_CoPt_tqFfNRegBuf: unqueued-sender-com-spec{data-element=CoPt_tqFfNRegBuf, can-invalidate=false, init-value=ConstantValue423}, provided-interface=IF_CoPt_tqFfNRegBuf
      P_IgSys_agIgCylPresMaxFlex: unqueued-sender-com-spec{data-element=IgSys_agIgCylPresMaxFlex, can-invalidate=false, init-value=ConstantValue425}, provided-interface=IF_IgSys_agIgCylPresMaxFlex
      P_TqDem_tqWhlPTDrvMinReq: unqueued-sender-com-spec{data-element=TqDem_tqWhlPTDrvMinReq, can-invalidate=false, init-value=ConstantValue427}, provided-interface=IF_TqDem_tqWhlPTDrvMinReq
      P_Ext_bAdFanAct: unqueued-sender-com-spec{data-element=Ext_bAdFanAct, can-invalidate=false, init-value=ConstantValue429}, provided-interface=IF_Ext_bAdFanAct
      P_IgSys_agIgOptmGas: unqueued-sender-com-spec{data-element=IgSys_agIgOptmGas, can-invalidate=false, init-value=ConstantValue431}, provided-interface=IF_IgSys_agIgOptmGas
      P_TqDem_tqWhlPTDrvReq: unqueued-sender-com-spec{data-element=TqDem_tqWhlPTDrvReq, can-invalidate=false, init-value=ConstantValue433}, provided-interface=IF_TqDem_tqWhlPTDrvReq
      P_CoReqStg_bEngASERstrtReq: unqueued-sender-com-spec{data-element=CoReqStg_bEngASERstrtReq, can-invalidate=false, init-value=ConstantValue435}, provided-interface=IF_CoReqStg_bEngASERstrtReq
      P_EOM_stCmbTdOff: unqueued-sender-com-spec{data-element=EOM_stCmbTdOff, can-invalidate=false, init-value=ConstantValue437}, provided-interface=IF_EOM_stCmbTdOff
      P_Blby_facStiRich: unqueued-sender-com-spec{data-element=Blby_facStiRich, can-invalidate=false, init-value=ConstantValue439}, provided-interface=IF_Blby_facStiRich
      P_CoPt_tqEfcCordLimExt_tqGBx: unqueued-sender-com-spec{data-element=CoPt_tqEfcCordLimExt_tqGBx, can-invalidate=false, init-value=ConstantValue441}, provided-interface=IF_CoPt_tqEfcCordLimExt_tqGBx
      P_CoCha_tqEfcReqExt: unqueued-sender-com-spec{data-element=CoCha_tqEfcReqExt, can-invalidate=false, init-value=ConstantValue443}, provided-interface=IF_CoCha_tqEfcReqExt
      P_RvAltMgt_stRvAltModReq: unqueued-sender-com-spec{data-element=RvAltMgt_stRvAltModReq, can-invalidate=false, init-value=ConstantValue445}, provided-interface=IF_RvAltMgt_stRvAltModReq
      P_VSCtl_tiCfmSupDVSRegReq: unqueued-sender-com-spec{data-element=VSCtl_tiCfmSupDVSRegReq, can-invalidate=false, init-value=ConstantValue447}, provided-interface=IF_VSCtl_tiCfmSupDVSRegReq
      P_TrbAct_rCtl: unqueued-sender-com-spec{data-element=TrbAct_rCtl, can-invalidate=false, init-value=ConstantValue449}, provided-interface=IF_TrbAct_rCtl
      P_RvAltMgt_tRvAltECUMes: unqueued-sender-com-spec{data-element=RvAltMgt_tRvAltECUMes, can-invalidate=false, init-value=ConstantValue451}, provided-interface=IF_RvAltMgt_tRvAltECUMes
      P_CoPtUH_bEngAsiReq: unqueued-sender-com-spec{data-element=CoPtUH_bEngAsiReq, can-invalidate=false, init-value=ConstantValue453}, provided-interface=IF_CoPtUH_bEngAsiReq
      P_RvAltMgt_bAntStopStrtWarn: unqueued-sender-com-spec{data-element=RvAltMgt_bAntStopStrtWarn, can-invalidate=false, init-value=ConstantValue455}, provided-interface=IF_RvAltMgt_bAntStopStrtWarn
      P_CoVlv_rOpBypCoVlvMes: unqueued-sender-com-spec{data-element=CoVlv_rOpBypCoVlvMes, can-invalidate=false, init-value=ConstantValue457}, provided-interface=IF_CoVlv_rOpBypCoVlvMes
      P_VSCtl_stCtl_aVehPotDVSReg: unqueued-sender-com-spec{data-element=VSCtl_stCtl_aVehPotDVSReg, can-invalidate=false, init-value=ConstantValue459}, provided-interface=IF_VSCtl_stCtl_aVehPotDVSReg
      P_TqEst_tqIdcEstim: unqueued-sender-com-spec{data-element=TqEst_tqIdcEstim, can-invalidate=false, init-value=ConstantValue461}, provided-interface=IF_TqEst_tqIdcEstim
      P_TqSys_bAcceDetAOSExt: unqueued-sender-com-spec{data-element=TqSys_bAcceDetAOSExt, can-invalidate=false, init-value=ConstantValue463}, provided-interface=IF_TqSys_bAcceDetAOSExt
      P_EngLim_tqIdcColdSmkRaw: unqueued-sender-com-spec{data-element=EngLim_tqIdcColdSmkRaw, can-invalidate=false, init-value=ConstantValue465}, provided-interface=IF_EngLim_tqIdcColdSmkRaw
      P_TPM_rAirLdReqGas: unqueued-sender-com-spec{data-element=TPM_rAirLdReqGas, can-invalidate=false, init-value=ConstantValue467}, provided-interface=IF_TPM_rAirLdReqGas
      P_AfuA_bFlexAdpAcv: unqueued-sender-com-spec{data-element=AfuA_bFlexAdpAcv, can-invalidate=false, init-value=ConstantValue469}, provided-interface=IF_AfuA_bFlexAdpAcv
      P_RvAltMgt_tqRvAltGenModMv: unqueued-sender-com-spec{data-element=RvAltMgt_tqRvAltGenModMv, can-invalidate=false, init-value=ConstantValue471}, provided-interface=IF_RvAltMgt_tqRvAltGenModMv
      P_InjSP_mfFuPoI2Req: unqueued-sender-com-spec{data-element=InjSP_mfFuPoI2Req, can-invalidate=false, init-value=ConstantValue473}, provided-interface=IF_InjSP_mfFuPoI2Req
      P_EngM_mfDsEGRCoEstim: unqueued-sender-com-spec{data-element=EngM_mfDsEGRCoEstim, can-invalidate=false, init-value=ConstantValue475}, provided-interface=IF_EngM_mfDsEGRCoEstim
      P_TqSys_bAcvCllExt: unqueued-sender-com-spec{data-element=TqSys_bAcvCllExt, can-invalidate=false, init-value=ConstantValue477}, provided-interface=IF_TqSys_bAcvCllExt
      P_Ext_bAcvGasMod: unqueued-sender-com-spec{data-element=Ext_bAcvGasMod, can-invalidate=false, init-value=ConstantValue479}, provided-interface=IF_Ext_bAcvGasMod
      P_InjSys_tqIdcMinFeas: unqueued-sender-com-spec{data-element=InjSys_tqIdcMinFeas, can-invalidate=false, init-value=ConstantValue481}, provided-interface=IF_InjSys_tqIdcMinFeas
      P_EngLim_tqIdcFLdUnlim: unqueued-sender-com-spec{data-element=EngLim_tqIdcFLdUnlim, can-invalidate=false, init-value=ConstantValue483}, provided-interface=IF_EngLim_tqIdcFLdUnlim
      P_RvAltMgt_nRvAltMes: unqueued-sender-com-spec{data-element=RvAltMgt_nRvAltMes, can-invalidate=false, init-value=ConstantValue485}, provided-interface=IF_RvAltMgt_nRvAltMes
      P_TqCha_tqAirTqIncReqExt: unqueued-sender-com-spec{data-element=TqCha_tqAirTqIncReqExt, can-invalidate=false, init-value=ConstantValue487}, provided-interface=IF_TqCha_tqAirTqIncReqExt
      P_TqDem_tqWhlPTDrvMaxReq: unqueued-sender-com-spec{data-element=TqDem_tqWhlPTDrvMaxReq, can-invalidate=false, init-value=ConstantValue489}, provided-interface=IF_TqDem_tqWhlPTDrvMaxReq
      P_PtLim_tqWhlPTMinCtla: unqueued-sender-com-spec{data-element=PtLim_tqWhlPTMinCtla, can-invalidate=false, init-value=ConstantValue491}, provided-interface=IF_PtLim_tqWhlPTMinCtla
      P_OAM_rOilDil: unqueued-sender-com-spec{data-element=OAM_rOilDil, can-invalidate=false, init-value=ConstantValue493}, provided-interface=IF_OAM_rOilDil
      P_Ext_tUsPFlt: unqueued-sender-com-spec{data-element=Ext_tUsPFlt, can-invalidate=false, init-value=ConstantValue495}, provided-interface=IF_Ext_tUsPFlt
      P_EOM_facItpolCur: unqueued-sender-com-spec{data-element=EOM_facItpolCur, can-invalidate=false, init-value=ConstantValue497}, provided-interface=IF_EOM_facItpolCur
      P_Blby_bCfHiMfBlby: unqueued-sender-com-spec{data-element=Blby_bCfHiMfBlby, can-invalidate=false, init-value=ConstantValue499}, provided-interface=IF_Blby_bCfHiMfBlby
      P_Tra_bNRegTyp: unqueued-sender-com-spec{data-element=Tra_bNRegTyp, can-invalidate=false, init-value=ConstantValue501}, provided-interface=IF_Tra_bNRegTyp
      P_IgSys_agIgMinThermoFlex: unqueued-sender-com-spec{data-element=IgSys_agIgMinThermoFlex, can-invalidate=false, init-value=ConstantValue503}, provided-interface=IF_IgSys_agIgMinThermoFlex
      P_Ext_facRhoFu: unqueued-sender-com-spec{data-element=Ext_facRhoFu, can-invalidate=false, init-value=ConstantValue505}, provided-interface=IF_Ext_facRhoFu
      P_VSSCtzMgt_bUcapSerAcvTest: unqueued-sender-com-spec{data-element=VSSCtzMgt_bUcapSerAcvTest, can-invalidate=false, init-value=ConstantValue507}, provided-interface=IF_VSSCtzMgt_bUcapSerAcvTest
      P_TqSys_facReqExhTempProt: unqueued-sender-com-spec{data-element=TqSys_facReqExhTempProt, can-invalidate=false, init-value=ConstantValue509}, provided-interface=IF_TqSys_facReqExhTempProt
      P_VSCtl_stVSMax: unqueued-sender-com-spec{data-element=VSCtl_stVSMax, can-invalidate=false, init-value=ConstantValue511}, provided-interface=IF_VSCtl_stVSMax
      P_PtLim_tqWhlThPTMin: unqueued-sender-com-spec{data-element=PtLim_tqWhlThPTMin, can-invalidate=false, init-value=ConstantValue513}, provided-interface=IF_PtLim_tqWhlThPTMin
      P_PredRstrt_noTDC: unqueued-sender-com-spec{data-element=PredRstrt_noTDC, can-invalidate=false, init-value=ConstantValue515}, provided-interface=IF_PredRstrt_noTDC
      P_Afts_bSpcFactOffDeacInh: unqueued-sender-com-spec{data-element=Afts_bSpcFactOffDeacInh, can-invalidate=false, init-value=ConstantValue517}, provided-interface=IF_Afts_bSpcFactOffDeacInh
      P_EngM_dstExVlvClrCor: unqueued-sender-com-spec{data-element=EngM_dstExVlvClrCor, can-invalidate=false, init-value=ConstantValue519}, provided-interface=IF_EngM_dstExVlvClrCor
      P_TqDem_tqWhlPTPreCoVSCtlReq: unqueued-sender-com-spec{data-element=TqDem_tqWhlPTPreCoVSCtlReq, can-invalidate=false, init-value=ConstantValue521}, provided-interface=IF_TqDem_tqWhlPTPreCoVSCtlReq
      P_Ext_stDirMoveVeh: unqueued-sender-com-spec{data-element=Ext_stDirMoveVeh, can-invalidate=false, init-value=ConstantValue523}, provided-interface=IF_Ext_stDirMoveVeh
      P_ExM_rGas: unqueued-sender-com-spec{data-element=ExM_rGas, can-invalidate=false, init-value=ConstantValue525}, provided-interface=IF_ExM_rGas
      P_Blby_bAcvStiRich: unqueued-sender-com-spec{data-element=Blby_bAcvStiRich, can-invalidate=false, init-value=ConstantValue527}, provided-interface=IF_Blby_bAcvStiRich
      P_ExM_cppIngGas: unqueued-sender-com-spec{data-element=ExM_cppIngGas, can-invalidate=false, init-value=ConstantValue529}, provided-interface=IF_ExM_cppIngGas
      P_CoPtASE_bAltStrtTypASEReq: unqueued-sender-com-spec{data-element=CoPtASE_bAltStrtTypASEReq, can-invalidate=false, init-value=ConstantValue531}, provided-interface=IF_CoPtASE_bAltStrtTypASEReq
      P_ExM_tEgMes: unqueued-sender-com-spec{data-element=ExM_tEgMes, can-invalidate=false, init-value=ConstantValue533}, provided-interface=IF_ExM_tEgMes
      P_CoPt_bInhEngStopProtManClu: unqueued-sender-com-spec{data-element=CoPt_bInhEngStopProtManClu, can-invalidate=false, init-value=ConstantValue535}, provided-interface=IF_CoPt_bInhEngStopProtManClu
      P_Veh_stHeatCoFlowReq: unqueued-sender-com-spec{data-element=Veh_stHeatCoFlowReq, can-invalidate=false, init-value=ConstantValue537}, provided-interface=IF_Veh_stHeatCoFlowReq
  271 x constant specification:
    ArrayConstantValue
      value:
        array specification ArrayConstantValue: type=rt_Array_UInt16_5_m0
          5 x integer literal, all with type=DT_ExM_prm_facFlex, value=0:
            Const
            Const{1..4}
    ArrayConstantValue141
      value:
        array specification ArrayConstantValue141: type=Array_5_UInt16
          5 x integer literal, all with type=DT_ExM_prm_facGas, value=0:
            Const
            Const{1..4}
    ArrayConstantValue235
      value:
        array specification ArrayConstantValue235: type=rt_Array_UInt8_10_m0
          10 x integer literal, all with type=DT_IgSys_prm_facFlex, value=0:
            Const
            Const{1..9}
    ConstantValue
      value:
        integer literal ConstantValue: type=DT_TqSys_tiTranCllExt, value=0
    ConstantValue1
      value:
        integer literal ConstantValue1: type=DT_Ext_stUcapChSpElMgt, value=0
    ConstantValue101
      value:
        integer literal ConstantValue101: type=DT_CoPt_tqEfcAirCordLimExtTqGBx, value=0
    ConstantValue103
      value:
        integer literal ConstantValue103: type=DT_TqDem_tqWhlPTPreCoVSCMaxReq, value=0
    ConstantValue105
      value:
        integer literal ConstantValue105: type=DT_Ext_tVSS, value=0
    ConstantValue107
      value:
        integer literal ConstantValue107: type=DT_EGRVlv_rOp, value=0
    ConstantValue109
      value:
        boolean literal ConstantValue109: type=DT_CoCha_bInhEGRExt, value=false
    ConstantValue11
      value:
        integer literal ConstantValue11: type=DT_CoVSCtl_tqSIPTar, value=-32000
    ConstantValue111
      value:
        integer literal ConstantValue111: type=DT_RvAltMgt_tRvAltStatEstim, value=-15
    ConstantValue113
      value:
        integer literal ConstantValue113: type=DT_EngM_tUsTrbEstimFil, value=0
    ConstantValue115
      value:
        boolean literal ConstantValue115: type=DT_Afts_bVSSCtzActrTestCmd, value=false
    ConstantValue117
      value:
        integer literal ConstantValue117: type=DT_Ext_stPwrLimCf, value=0
    ConstantValue119
      value:
        integer literal ConstantValue119: type=DT_ExM_molMassExGas, value=3840
    ConstantValue121
      value:
        integer literal ConstantValue121: type=DT_TqSys_tqCkEfcAirFilExt, value=0
    ConstantValue123
      value:
        boolean literal ConstantValue123: type=DT_Afts_bRstTrbCaseDmgReq, value=false
    ConstantValue125
      value:
        boolean literal ConstantValue125: type=DT_SftyMgt_bDeacIrvVSLim, value=false
    ConstantValue127
      value:
        integer literal ConstantValue127: type=DT_IgSys_agIgCmbModOfsMinThermo, value=0
    ConstantValue129
      value:
        integer literal ConstantValue129: type=DT_PtLim_tqWhlPTMinNotCtla, value=0
    ConstantValue13
      value:
        integer literal ConstantValue13: type=DT_VehEst_rTqWhlPTRe, value=0
    ConstantValue131
      value:
        integer literal ConstantValue131: type=DT_Stg_tSysStrWhl, value=0
    ConstantValue133
      value:
        boolean literal ConstantValue133: type=DT_CoEmSTT_bEngASERstrtReq, value=false
    ConstantValue135
      value:
        boolean literal ConstantValue135: type=DT_GlwCtl_bEngRunAuth, value=true
    ConstantValue137
      value:
        boolean literal ConstantValue137: type=DT_CoPtUH_bEngAsiReqExt, value=false
    ConstantValue139
      value:
        boolean literal ConstantValue139: type=DT_CoEmSTT_bAuthBoost, value=false
    ConstantValue143
      value:
        boolean literal ConstantValue143: type=DT_Afts_bRstCylHdDmgReq, value=false
    ConstantValue145
      value:
        integer literal ConstantValue145: type=DT_ExM_cppExFlex, value=2000
    ConstantValue147
      value:
        integer literal ConstantValue147: type=DT_VSCtl_stVSReg, value=0
    ConstantValue149
      value:
        boolean literal ConstantValue149: type=DT_CoSync_bAgEsCfm, value=false
    ConstantValue15
      value:
        integer literal ConstantValue15: type=DT_EngM_mfEgEstim, value=0
    ConstantValue151
      value:
        boolean literal ConstantValue151: type=DT_RvAltMgt_bStopStrtWarn, value=false
    ConstantValue153
      value:
        integer literal ConstantValue153: type=DT_EOM_idxBas2InjCur, value=1
    ConstantValue155
      value:
        integer literal ConstantValue155: type=DT_TqSys_noCylCutAuthExt, value=0
    ConstantValue157
      value:
        integer literal ConstantValue157: type=DT_CoReqDmpr_stEngStopAuth, value=1
    ConstantValue159
      value:
        integer literal ConstantValue159: type=DT_VSCtl_stVSLim, value=0
    ConstantValue161
      value:
        boolean literal ConstantValue161: type=DT_VehEst_bORng_nPT, value=false
    ConstantValue163
      value:
        integer literal ConstantValue163: type=DT_IgSys_agIgOptmFlex, value=96
    ConstantValue165
      value:
        boolean literal ConstantValue165: type=DT_Afts_bRst_stDeacVSLimReq2, value=false
    ConstantValue167
      value:
        boolean literal ConstantValue167: type=DT_Ext_bAvlTqWhlPT_no2, value=false
    ConstantValue169
      value:
        integer literal ConstantValue169: type=DT_CoPtFH_stPwt, value=0
    ConstantValue17
      value:
        boolean literal ConstantValue17: type=DT_Tra_bInhAC, value=false
    ConstantValue171
      value:
        boolean literal ConstantValue171: type=DT_TqSys_bInhBrio, value=false
    ConstantValue173
      value:
        integer literal ConstantValue173: type=DT_AfuA_rEthWoutExct, value=0
    ConstantValue175
      value:
        integer literal ConstantValue175: type=DT_ExM_facIgCorGas, value=49151
    ConstantValue177
      value:
        boolean literal ConstantValue177: type=DT_Ext_bAvlTqWhlPT_no1, value=false
    ConstantValue179
      value:
        boolean literal ConstantValue179: type=DT_Afts_bRst_stDeacVSRegReq2, value=false
    ConstantValue181
      value:
        integer literal ConstantValue181: type=DT_CoPt_nTarIdlCVC, value=0
    ConstantValue183
      value:
        boolean literal ConstantValue183: type=DT_EngReqH_bEngStallAuth, value=true
    ConstantValue185
      value:
        boolean literal ConstantValue185: type=DT_TqCmp_bOpFSFReq_tAir, value=false
    ConstantValue187
      value:
        integer literal ConstantValue187: type=DT_IgSys_agIgMinThermoGas, value=0
    ConstantValue189
      value:
        boolean literal ConstantValue189: type=DT_TqSys_bDeceDetAOSExt, value=false
    ConstantValue19
      value:
        integer literal ConstantValue19: type=DT_ExM_molMassInWoutRgGas, value=3712
    ConstantValue191
      value:
        integer literal ConstantValue191: type=DT_TqSys_nOfsLauchIdlTakeOff, value=0
    ConstantValue193
      value:
        boolean literal ConstantValue193: type=DT_Brk_bBrkAuto, value=false
    ConstantValue195
      value:
        boolean literal ConstantValue195: type=DT_Ext_bEspVehVld, value=true
    ConstantValue197
      value:
        integer literal ConstantValue197: type=DT_FARSp_rDeltaMixtStiTWCSp, value=0
    ConstantValue199
      value:
        integer literal ConstantValue199: type=DT_RvAltMgt_uRvAltMes, value=170
    ConstantValue201
      value:
        boolean literal ConstantValue201: type=DT_CoReqDamp_bEngStallAuth, value=true
    ConstantValue203
      value:
        integer literal ConstantValue203: type=DT_ElSysCo_rSpdFanReq, value=0
    ConstantValue205
      value:
        boolean literal ConstantValue205: type=DT_CoPt_bDeacCllExt, value=false
    ConstantValue207
      value:
        integer literal ConstantValue207: type=DT_CoVlv_rOpRadCoVlvMes, value=0
    ConstantValue209
      value:
        integer literal ConstantValue209: type=DT_EOM_stEngModReq, value=1
    ConstantValue21
      value:
        integer literal ConstantValue21: type=DT_EngLim_tqCkEfcStatLimExt, value=0
    ConstantValue211
      value:
        integer literal ConstantValue211: type=DT_CoCha_tqEfcAirReqExt, value=0
    ConstantValue213
      value:
        integer literal ConstantValue213: type=DT_Tra_stVehDirEstim, value=1
    ConstantValue215
      value:
        integer literal ConstantValue215: type=DT_RvAltMgt_stRvAltRstrtFbCmd, value=0
    ConstantValue217
      value:
        boolean literal ConstantValue217: type=DT_Ext_bAvrFrntWhlVld, value=true
    ConstantValue219
      value:
        integer literal ConstantValue219: type=DT_EngLim_tqIdcSmkLim, value=32000
    ConstantValue221
      value:
        boolean literal ConstantValue221: type=DT_OilTqCf_bPresOilReqCf, value=false
    ConstantValue223
      value:
        boolean literal ConstantValue223: type=DT_Afts_bUcapChgIdc, value=false
    ConstantValue225
      value:
        boolean literal ConstantValue225: type=DT_Ext_bFrntLeftWhlVehVld, value=true
    ConstantValue227
      value:
        integer literal ConstantValue227: type=DT_EngM_dstInVlvClrCor, value=0
    ConstantValue229
      value:
        boolean literal ConstantValue229: type=DT_Afts_bRstExMnfDmgReq, value=false
    ConstantValue23
      value:
        integer literal ConstantValue23: type=DT_ExM_molMassExFlex, value=3840
    ConstantValue231
      value:
        integer literal ConstantValue231: type=DT_EngM_facCorOfsEfc, value=0
    ConstantValue233
      value:
        boolean literal ConstantValue233: type=DT_Tra_bSpdVehLoDet, value=false
    ConstantValue237
      value:
        integer literal ConstantValue237: type=DT_EOM_idxBas1InjCur, value=1
    ConstantValue239
      value:
        integer literal ConstantValue239: type=DT_InjSP_mfFuPoI1Req, value=0
    ConstantValue241
      value:
        boolean literal ConstantValue241: type=DT_Ext_bTqAltEstimElSys, value=true
    ConstantValue243
      value:
        boolean literal ConstantValue243: type=DT_CoPt_bAcvTqNCordBuf, value=false
    ConstantValue245
      value:
        integer literal ConstantValue245: type=DT_Ext_stSpdFanPFltReq, value=0
    ConstantValue247
      value:
        boolean literal ConstantValue247: type=DT_VehEst_bCtlTqWhlPT, value=false
    ConstantValue249
      value:
        integer literal ConstantValue249: type=DT_IgSys_rTarStatIgSpEff, value=1024
    ConstantValue25
      value:
        integer literal ConstantValue25: type=DT_VSSCtzMgt_uUcapMes, value=0
    ConstantValue251
      value:
        integer literal ConstantValue251: type=DT_EngLim_tqIdcEngLim, value=32000
    ConstantValue253
      value:
        integer literal ConstantValue253: type=DT_TqSys_tqCkEfcFilExt, value=0
    ConstantValue255
      value:
        boolean literal ConstantValue255: type=DT_PARM_bEngRstrtAutnAvl, value=false
    ConstantValue257
      value:
        integer literal ConstantValue257: type=DT_TqSys_stDrivFilPhaExt, value=0
    ConstantValue259
      value:
        integer literal ConstantValue259: type=DT_EGRVlv_rOpEGRReq, value=0
    ConstantValue261
      value:
        integer literal ConstantValue261: type=DT_VSSCtzMgt_tUcapMes, value=40
    ConstantValue263
      value:
        integer literal ConstantValue263: type=DT_VSCtl_rCtlTqWhlPTPotDVSReg, value=0
    ConstantValue265
      value:
        boolean literal ConstantValue265: type=DT_Ext_bDiDrivFilReq, value=false
    ConstantValue267
      value:
        integer literal ConstantValue267: type=DT_VSCtl_tiCfmSdwnDVSRegReq, value=0
    ConstantValue269
      value:
        boolean literal ConstantValue269: type=DT_CoReqVeh_bEngStallAuth, value=true
    ConstantValue27
      value:
        boolean literal ConstantValue27: type=DT_Ext_bAvlTqWhlPT_no3, value=false
    ConstantValue271
      value:
        boolean literal ConstantValue271: type=DT_Blby_bIncIdlSpd, value=false
    ConstantValue273
      value:
        integer literal ConstantValue273: type=DT_CoVlv_rOpHeatCoVlvMes, value=0
    ConstantValue275
      value:
        boolean literal ConstantValue275: type=DT_CoReqDmpr_bEngRStrtReq, value=false
    ConstantValue277
      value:
        integer literal ConstantValue277: type=DT_TqSys_nTarDynIdl, value=0
    ConstantValue279
      value:
        boolean literal ConstantValue279: type=DT_Ext_bGslEngPrepReq, value=false
    ConstantValue281
      value:
        integer literal ConstantValue281: type=DT_EGRVlv_stEGRMod, value=1
    ConstantValue283
      value:
        boolean literal ConstantValue283: type=DT_TqSys_bInhTqDemSptMod, value=false
    ConstantValue285
      value:
        integer literal ConstantValue285: type=DT_VSSCtzMgt_stVSSCtzAcvSt, value=0
    ConstantValue287
      value:
        boolean literal ConstantValue287: type=DT_Ext_bRawMainWaPmpSt, value=true
    ConstantValue289
      value:
        integer literal ConstantValue289: type=DT_VehEst_tqWhlPTReq, value=0
    ConstantValue29
      value:
        integer literal ConstantValue29: type=DT_VSCtl_stDVSRegExtd, value=0
    ConstantValue291
      value:
        boolean literal ConstantValue291: type=DT_Afts_bSpcFactOnDeacInh, value=false
    ConstantValue293
      value:
        integer literal ConstantValue293: type=DT_PtLim_tqWhlPTMaxNotCtla, value=0
    ConstantValue295
      value:
        integer literal ConstantValue295: type=DT_TqDem_tqWhlPTPreCoVSCMinReq, value=0
    ConstantValue297
      value:
        boolean literal ConstantValue297: type=DT_CoReqCha_bEngASERstrtReq, value=false
    ConstantValue299
      value:
        integer literal ConstantValue299: type=DT_ExM_cppIngFlex, value=2000
    ConstantValue3
      value:
        integer literal ConstantValue3: type=DT_WaTEst_rErrTCo, value=0
    ConstantValue301
      value:
        integer literal ConstantValue301: type=DT_TqSys_tqAOSCVC, value=0
    ConstantValue303
      value:
        boolean literal ConstantValue303: type=DT_TqSys_bDeceAcvExt, value=false
    ConstantValue305
      value:
        integer literal ConstantValue305: type=DT_Blby_mfFuStmCmpAirSys, value=0
    ConstantValue307
      value:
        integer literal ConstantValue307: type=DT_ExM_facLamCorFlex, value=16384
    ConstantValue309
      value:
        integer literal ConstantValue309: type=DT_IgSys_agIgMinCmbGas, value=0
    ConstantValue31
      value:
        integer literal ConstantValue31: type=DT_AfuA_rEthStoich, value=32768
    ConstantValue311
      value:
        integer literal ConstantValue311: type=DT_MCT_tqFrntMchEstim, value=0
    ConstantValue313
      value:
        boolean literal ConstantValue313: type=DT_CoPtFH_bEngRunReq, value=false
    ConstantValue315
      value:
        boolean literal ConstantValue315: type=DT_Afts_bRst_stDeacVSMaxReq1, value=false
    ConstantValue317
      value:
        integer literal ConstantValue317: type=DT_EngM_facCorSlopEfc, value=32768
    ConstantValue319
      value:
        integer literal ConstantValue319: type=DT_CoPt_facAntiJerkExt, value=256
    ConstantValue321
      value:
        integer literal ConstantValue321: type=DT_TqDem_tqWhlPTDrvMinReqRaw, value=0
    ConstantValue323
      value:
        boolean literal ConstantValue323: type=DT_CoPtASE_bEngStrtTypASEReq, value=false
    ConstantValue325
      value:
        integer literal ConstantValue325: type=DT_OilTqCf_facNum, value=0
    ConstantValue327
      value:
        integer literal ConstantValue327: type=DT_CoVSCtl_rAccPEngExt, value=0
    ConstantValue329
      value:
        integer literal ConstantValue329: type=DT_VehEst_spdVehCrit, value=255
    ConstantValue33
      value:
        boolean literal ConstantValue33: type=DT_VSSCtzMgt_bAcvElCnsReq, value=false
    ConstantValue331
      value:
        boolean literal ConstantValue331: type=DT_Afts_bRst_stDeacVSLimReq1, value=false
    ConstantValue333
      value:
        integer literal ConstantValue333: type=DT_Ext_rCorSoCHyb, value=0
    ConstantValue335
      value:
        boolean literal ConstantValue335: type=DT_Ext_bFrntRightWhlVehVld, value=true
    ConstantValue337
      value:
        integer literal ConstantValue337: type=DT_VSSCtzMgt_rUcapSoHTreat, value=100
    ConstantValue339
      value:
        boolean literal ConstantValue339: type=DT_GlwCtl_bEngRunReq, value=false
    ConstantValue341
      value:
        integer literal ConstantValue341: type=DT_TqLimEM_tqLimEMExt, value=0
    ConstantValue343
      value:
        integer literal ConstantValue343: type=DT_TqSys_tqCkIdlMin, value=0
    ConstantValue345
      value:
        boolean literal ConstantValue345: type=DT_PFlt_bPFltRgnSrvReq, value=false
    ConstantValue347
      value:
        boolean literal ConstantValue347: type=DT_Ext_bTyreWarn, value=false
    ConstantValue349
      value:
        boolean literal ConstantValue349: type=DT_Blby_bDecPfu, value=false
    ConstantValue35
      value:
        integer literal ConstantValue35: type=DT_ExM_molMassInWoutRgFlex, value=3712
    ConstantValue351
      value:
        integer literal ConstantValue351: type=DT_EngLim_tqIdcEngProt, value=32000
    ConstantValue353
      value:
        boolean literal ConstantValue353: type=DT_RvAltMgt_bIdcVldCurGenMod, value=true
    ConstantValue355
      value:
        integer literal ConstantValue355: type=DT_ExM_tExFlex, value=24864
    ConstantValue357
      value:
        integer literal ConstantValue357: type=DT_ExM_facIgCorFlex, value=16384
    ConstantValue359
      value:
        integer literal ConstantValue359: type=DT_VSCtl_aVehPotDVSRegReq, value=-10240
    ConstantValue361
      value:
        integer literal ConstantValue361: type=DT_TqCmp_pwrACAuxLoss, value=0
    ConstantValue363
      value:
        integer literal ConstantValue363: type=DT_TqSys_tqIncCllExt, value=0
    ConstantValue365
      value:
        boolean literal ConstantValue365: type=DT_VSCtl_stCtl_aVehDVSReg, value=false
    ConstantValue367
      value:
        boolean literal ConstantValue367: type=DT_Afts_bRst_stDeacVSRegReq1, value=false
    ConstantValue369
      value:
        integer literal ConstantValue369: type=DT_EngLim_tqIdcSfty, value=32000
    ConstantValue37
      value:
        integer literal ConstantValue37: type=DT_VehEst_tqWhlPTRealEstim, value=0
    ConstantValue371
      value:
        integer literal ConstantValue371: type=DT_IgSys_agIgMaxGas, value=96
    ConstantValue373
      value:
        integer literal ConstantValue373: type=DT_Brk_tqWhlBrkEstim, value=0
    ConstantValue375
      value:
        boolean literal ConstantValue375: type=DT_Tra_bVoltAltBoostReqGBx, value=false
    ConstantValue377
      value:
        integer literal ConstantValue377: type=DT_WaTEst_tMtlEngEstim, value=0
    ConstantValue379
      value:
        boolean literal ConstantValue379: type=DT_Afts_bRstCylBlockDmgReq, value=false
    ConstantValue381
      value:
        integer literal ConstantValue381: type=DT_TqSys_tqThdPha3Ext, value=0
    ConstantValue383
      value:
        integer literal ConstantValue383: type=DT_ExM_pMes, value=12662
    ConstantValue385
      value:
        integer literal ConstantValue385: type=DT_PtLim_tqWhlThPTPotMin, value=0
    ConstantValue387
      value:
        integer literal ConstantValue387: type=DT_TqSys_tqCkIdlMax, value=0
    ConstantValue389
      value:
        integer literal ConstantValue389: type=DT_PtLim_tqWhlPTPotMinCtla, value=0
    ConstantValue39
      value:
        integer literal ConstantValue39: type=DT_TqSys_facReqFuelRunDry, value=128
    ConstantValue391
      value:
        integer literal ConstantValue391: type=DT_IgSys_agIgMinCmbFlex, value=0
    ConstantValue393
      value:
        integer literal ConstantValue393: type=DT_PtLim_tqWhlPTPotMaxCtla_no1, value=0
    ConstantValue395
      value:
        integer literal ConstantValue395: type=DT_PtLim_tqWhlPTPotMaxCtla_no2, value=0
    ConstantValue397
      value:
        boolean literal ConstantValue397: type=DT_ElSysCo_bOpFSFReq, value=false
    ConstantValue399
      value:
        integer literal ConstantValue399: type=DT_RvAltMgt_tqRvAltGenModEstim, value=0
    ConstantValue401
      value:
        boolean literal ConstantValue401: type=DT_TqAdp_bFrzAdpACAuxOn, value=false
    ConstantValue403
      value:
        integer literal ConstantValue403: type=DT_ExM_cppExGas, value=2000
    ConstantValue405
      value:
        integer literal ConstantValue405: type=DT_VSSCtzMgt_resVSSCtzEstim, value=205
    ConstantValue407
      value:
        integer literal ConstantValue407: type=DT_AfuA_rFlex, value=0
    ConstantValue409
      value:
        integer literal ConstantValue409: type=DT_IgSys_agIgMaxFlex, value=96
    ConstantValue41
      value:
        integer literal ConstantValue41: type=DT_TqSys_stStrtEngTyp, value=0
    ConstantValue411
      value:
        integer literal ConstantValue411: type=DT_ExM_facLamCorGas, value=49151
    ConstantValue413
      value:
        integer literal ConstantValue413: type=DT_TqSys_tqCkDeceIniExt, value=0
    ConstantValue415
      value:
        integer literal ConstantValue415: type=DT_TqCha_tqAirTqDecReqExt, value=32000
    ConstantValue417
      value:
        integer literal ConstantValue417: type=DT_AirSys_rOpEGRCoBypReq, value=0
    ConstantValue419
      value:
        integer literal ConstantValue419: type=DT_Ext_tECTSp, value=0
    ConstantValue421
      value:
        integer literal ConstantValue421: type=DT_VSCtl_aVehDVSRegReq, value=-10240
    ConstantValue423
      value:
        integer literal ConstantValue423: type=DT_CoPt_tqFfNRegBuf, value=0
    ConstantValue425
      value:
        integer literal ConstantValue425: type=DT_IgSys_agIgCylPresMaxFlex, value=255
    ConstantValue427
      value:
        integer literal ConstantValue427: type=DT_TqDem_tqWhlPTDrvMinReq, value=0
    ConstantValue429
      value:
        boolean literal ConstantValue429: type=DT_Ext_bAdFanAct, value=false
    ConstantValue43
      value:
        integer literal ConstantValue43: type=DT_EOM_stCmbMod, value=3
    ConstantValue431
      value:
        integer literal ConstantValue431: type=DT_IgSys_agIgOptmGas, value=96
    ConstantValue433
      value:
        integer literal ConstantValue433: type=DT_TqDem_tqWhlPTDrvReq, value=0
    ConstantValue435
      value:
        boolean literal ConstantValue435: type=DT_CoReqStg_bEngASERstrtReq, value=false
    ConstantValue437
      value:
        integer literal ConstantValue437: type=DT_EOM_stCmbTdOff, value=15
    ConstantValue439
      value:
        integer literal ConstantValue439: type=DT_Blby_facStiRich, value=32768
    ConstantValue441
      value:
        integer literal ConstantValue441: type=DT_CoPt_tqEfcCordLimExt_tqGBx, value=0
    ConstantValue443
      value:
        integer literal ConstantValue443: type=DT_CoCha_tqEfcReqExt, value=0
    ConstantValue445
      value:
        integer literal ConstantValue445: type=DT_RvAltMgt_stRvAltModReq, value=0
    ConstantValue447
      value:
        integer literal ConstantValue447: type=DT_VSCtl_tiCfmSupDVSRegReq, value=0
    ConstantValue449
      value:
        integer literal ConstantValue449: type=DT_TrbAct_rCtl, value=0
    ConstantValue45
      value:
        boolean literal ConstantValue45: type=DT_CoReqStg_bEngStallAuth, value=true
    ConstantValue451
      value:
        integer literal ConstantValue451: type=DT_RvAltMgt_tRvAltECUMes, value=-1
    ConstantValue453
      value:
        boolean literal ConstantValue453: type=DT_CoPtUH_bEngAsiReq, value=false
    ConstantValue455
      value:
        boolean literal ConstantValue455: type=DT_RvAltMgt_bAntStopStrtWarn, value=false
    ConstantValue457
      value:
        integer literal ConstantValue457: type=DT_CoVlv_rOpBypCoVlvMes, value=0
    ConstantValue459
      value:
        integer literal ConstantValue459: type=DT_VSCtl_stCtl_aVehPotDVSReg, value=0
    ConstantValue461
      value:
        integer literal ConstantValue461: type=DT_TqEst_tqIdcEstim, value=0
    ConstantValue463
      value:
        boolean literal ConstantValue463: type=DT_TqSys_bAcceDetAOSExt, value=false
    ConstantValue465
      value:
        integer literal ConstantValue465: type=DT_EngLim_tqIdcColdSmkRaw, value=0
    ConstantValue467
      value:
        integer literal ConstantValue467: type=DT_TPM_rAirLdReqGas, value=49152
    ConstantValue469
      value:
        boolean literal ConstantValue469: type=DT_AfuA_bFlexAdpAcv, value=false
    ConstantValue47
      value:
        boolean literal ConstantValue47: type=DT_CoPtFH_bEngStopReq, value=true
    ConstantValue471
      value:
        integer literal ConstantValue471: type=DT_RvAltMgt_tqRvAltGenModMv, value=0
    ConstantValue473
      value:
        integer literal ConstantValue473: type=DT_InjSP_mfFuPoI2Req, value=0
    ConstantValue475
      value:
        integer literal ConstantValue475: type=DT_EngM_mfDsEGRCoEstim, value=0
    ConstantValue477
      value:
        boolean literal ConstantValue477: type=DT_TqSys_bAcvCllExt, value=false
    ConstantValue479
      value:
        boolean literal ConstantValue479: type=DT_Ext_bAcvGasMod, value=false
    ConstantValue481
      value:
        integer literal ConstantValue481: type=DT_InjSys_tqIdcMinFeas, value=32000
    ConstantValue483
      value:
        integer literal ConstantValue483: type=DT_EngLim_tqIdcFLdUnlim, value=0
    ConstantValue485
      value:
        integer literal ConstantValue485: type=DT_RvAltMgt_nRvAltMes, value=0
    ConstantValue487
      value:
        integer literal ConstantValue487: type=DT_TqCha_tqAirTqIncReqExt, value=-32000
    ConstantValue489
      value:
        integer literal ConstantValue489: type=DT_TqDem_tqWhlPTDrvMaxReq, value=0
    ConstantValue49
      value:
        boolean literal ConstantValue49: type=DT_Veh_bHeatWaPmpReq, value=false
    ConstantValue491
      value:
        integer literal ConstantValue491: type=DT_PtLim_tqWhlPTMinCtla, value=0
    ConstantValue493
      value:
        integer literal ConstantValue493: type=DT_OAM_rOilDil, value=0
    ConstantValue495
      value:
        integer literal ConstantValue495: type=DT_Ext_tUsPFlt, value=0
    ConstantValue497
      value:
        integer literal ConstantValue497: type=DT_EOM_facItpolCur, value=0
    ConstantValue499
      value:
        boolean literal ConstantValue499: type=DT_Blby_bCfHiMfBlby, value=false
    ConstantValue5
      value:
        integer literal ConstantValue5: type=DT_RvAltMgt_iRvAltGenModEstim, value=0
    ConstantValue501
      value:
        boolean literal ConstantValue501: type=DT_Tra_bNRegTyp, value=true
    ConstantValue503
      value:
        integer literal ConstantValue503: type=DT_IgSys_agIgMinThermoFlex, value=0
    ConstantValue505
      value:
        integer literal ConstantValue505: type=DT_Ext_facRhoFu, value=127
    ConstantValue507
      value:
        boolean literal ConstantValue507: type=DT_VSSCtzMgt_bUcapSerAcvTest, value=true
    ConstantValue509
      value:
        integer literal ConstantValue509: type=DT_TqSys_facReqExhTempProt, value=128
    ConstantValue51
      value:
        integer literal ConstantValue51: type=DT_EngLim_tqIdcLimMin, value=32000
    ConstantValue511
      value:
        integer literal ConstantValue511: type=DT_VSCtl_stVSMax, value=0
    ConstantValue513
      value:
        integer literal ConstantValue513: type=DT_PtLim_tqWhlThPTMin, value=0
    ConstantValue515
      value:
        integer literal ConstantValue515: type=DT_PredRstrt_noTDC, value=3
    ConstantValue517
      value:
        boolean literal ConstantValue517: type=DT_Afts_bSpcFactOffDeacInh, value=true
    ConstantValue519
      value:
        integer literal ConstantValue519: type=DT_EngM_dstExVlvClrCor, value=0
    ConstantValue521
      value:
        integer literal ConstantValue521: type=DT_TqDem_tqWhlPTPreCoVSCtlReq, value=0
    ConstantValue523
      value:
        integer literal ConstantValue523: type=DT_Ext_stDirMoveVeh, value=0
    ConstantValue525
      value:
        integer literal ConstantValue525: type=DT_ExM_rGas, value=0
    ConstantValue527
      value:
        boolean literal ConstantValue527: type=DT_Blby_bAcvStiRich, value=false
    ConstantValue529
      value:
        integer literal ConstantValue529: type=DT_ExM_cppIngGas, value=2000
    ConstantValue53
      value:
        boolean literal ConstantValue53: type=DT_PFlt_bPFltRgnReq, value=false
    ConstantValue531
      value:
        boolean literal ConstantValue531: type=DT_CoPtASE_bAltStrtTypASEReq, value=false
    ConstantValue533
      value:
        integer literal ConstantValue533: type=DT_ExM_tEgMes, value=15264
    ConstantValue535
      value:
        boolean literal ConstantValue535: type=DT_CoPt_bInhEngStopProtManClu, value=false
    ConstantValue537
      value:
        integer literal ConstantValue537: type=DT_Veh_stHeatCoFlowReq, value=0
    ConstantValue55
      value:
        boolean literal ConstantValue55: type=DT_CoReqCha_bEngStallAuth, value=true
    ConstantValue57
      value:
        boolean literal ConstantValue57: type=DT_Ext_bDetLoWhlGrip, value=false
    ConstantValue59
      value:
        integer literal ConstantValue59: type=DT_VSSCtzMgt_stVSSCtzFctLvl, value=0
    ConstantValue61
      value:
        integer literal ConstantValue61: type=DT_RvAltMgt_nRvAltMv, value=0
    ConstantValue63
      value:
        boolean literal ConstantValue63: type=DT_TqSys_bAcceClrCrossAOSExt, value=false
    ConstantValue65
      value:
        boolean literal ConstantValue65: type=DT_Afts_bRst_stDeacVSMaxReq2, value=false
    ConstantValue67
      value:
        integer literal ConstantValue67: type=DT_Brk_tqWhlBrkReq, value=0
    ConstantValue69
      value:
        boolean literal ConstantValue69: type=DT_EGRVlv_bAcvClsEGRReq, value=true
    ConstantValue7
      value:
        boolean literal ConstantValue7: type=DT_Tra_bEngCrawlAuth, value=false
    ConstantValue71
      value:
        integer literal ConstantValue71: type=DT_VSSCtzMgt_stUcapDchaRslt, value=0
    ConstantValue73
      value:
        integer literal ConstantValue73: type=DT_RvAltMgt_tqRstrtMaxEstim, value=0
    ConstantValue75
      value:
        integer literal ConstantValue75: type=DT_TqSys_tqCkIdl, value=0
    ConstantValue77
      value:
        integer literal ConstantValue77: type=DT_OilTqCf_facDen, value=0
    ConstantValue79
      value:
        integer literal ConstantValue79: type=DT_PredRstrt_tiMax2TDC, value=0
    ConstantValue81
      value:
        integer literal ConstantValue81: type=DT_CoVSCtl_tqIdcSIPTar, value=0
    ConstantValue83
      value:
        integer literal ConstantValue83: type=DT_TqSys_nOfsFFL, value=0
    ConstantValue85
      value:
        boolean literal ConstantValue85: type=DT_EGRVlv_bClnEGRFoul, value=false
    ConstantValue87
      value:
        boolean literal ConstantValue87: type=DT_TqLimUH_bAcvUnBlsEng, value=false
    ConstantValue89
      value:
        integer literal ConstantValue89: type=DT_PtLim_tqWhlPTMaxCtla, value=0
    ConstantValue9
      value:
        integer literal ConstantValue9: type=DT_AfuA_rEthWiExct, value=0
    ConstantValue91
      value:
        boolean literal ConstantValue91: type=DT_TqSys_bIdlAcv, value=false
    ConstantValue93
      value:
        integer literal ConstantValue93: type=DT_ExM_tExFlexOfs, value=-1
    ConstantValue95
      value:
        boolean literal ConstantValue95: type=DT_CoReqVeh_bEngASERstrtReq, value=false
    ConstantValue97
      value:
        integer literal ConstantValue97: type=DT_TqEst_tqIdcStrt, value=0
    ConstantValue99
      value:
        integer literal ConstantValue99: type=DT_ExM_tExGas, value=0
  internal behavior IB_EBStub: component=EBSTUB
    mode switch event EV_EBStub_001_MSE: start-on-event=RE_EBStub_001_MSE, activation=ENTRY, mode=R_EcuM_CurrentMode.currentMode.RUN
    runnable RE_EBStub_001_MSE
      271 x data send point:
        ds_TqLimEM_tqLimEMExt: data-element=P_TqLimEM_tqLimEMExt.TqLimEM_tqLimEMExt
        ds_PtLim_tqWhlPTPotMaxCtla_no1: data-element=P_PtLim_tqWhlPTPotMaxCtla_no1.PtLim_tqWhlPTPotMaxCtla_no1
        ds_CoPtFH_stPwt: data-element=P_CoPtFH_stPwt.CoPtFH_stPwt
        ds_Ext_bRawMainWaPmpSt: data-element=P_Ext_bRawMainWaPmpSt.Ext_bRawMainWaPmpSt
        ds_RvAltMgt_bAntStopStrtWarn: data-element=P_RvAltMgt_bAntStopStrtWarn.RvAltMgt_bAntStopStrtWarn
        ds_IgSys_rTarStatIgSpEff: data-element=P_IgSys_rTarStatIgSpEff.IgSys_rTarStatIgSpEff
        ds_TqSys_bDeceAcvExt: data-element=P_TqSys_bDeceAcvExt.TqSys_bDeceAcvExt
        ds_CoVlv_rOpRadCoVlvMes: data-element=P_CoVlv_rOpRadCoVlvMes.CoVlv_rOpRadCoVlvMes
        ds_Blby_facStiRich: data-element=P_Blby_facStiRich.Blby_facStiRich
        ds_CoReqStg_bEngStallAuth: data-element=P_CoReqStg_bEngStallAuth.CoReqStg_bEngStallAuth
        ds_OilTqCf_facDen: data-element=P_OilTqCf_facDen.OilTqCf_facDen
        ds_IgSys_agIgMaxGas: data-element=P_IgSys_agIgMaxGas.IgSys_agIgMaxGas
        ds_TqDem_tqWhlPTDrvMinReq: data-element=P_TqDem_tqWhlPTDrvMinReq.TqDem_tqWhlPTDrvMinReq
        ds_PredRstrt_noTDC: data-element=P_PredRstrt_noTDC.PredRstrt_noTDC
        ds_Afts_bSpcFactOffDeacInh: data-element=P_Afts_bSpcFactOffDeacInh.Afts_bSpcFactOffDeacInh
        ds_RvAltMgt_tRvAltECUMes: data-element=P_RvAltMgt_tRvAltECUMes.RvAltMgt_tRvAltECUMes
        ds_CoReqStg_bEngASERstrtReq: data-element=P_CoReqStg_bEngASERstrtReq.CoReqStg_bEngASERstrtReq
        ds_Blby_bAcvStiRich: data-element=P_Blby_bAcvStiRich.Blby_bAcvStiRich
        ds_TrbAct_rCtl: data-element=P_TrbAct_rCtl.TrbAct_rCtl
        ds_ExM_cppExGas: data-element=P_ExM_cppExGas.ExM_cppExGas
        ds_Blby_mfFuStmCmpAirSys: data-element=P_Blby_mfFuStmCmpAirSys.Blby_mfFuStmCmpAirSys
        ds_Afts_bRstExMnfDmgReq: data-element=P_Afts_bRstExMnfDmgReq.Afts_bRstExMnfDmgReq
        ds_TqSys_tqCkIdlMax: data-element=P_TqSys_tqCkIdlMax.TqSys_tqCkIdlMax
        ds_VehEst_bORng_nPT: data-element=P_VehEst_bORng_nPT.VehEst_bORng_nPT
        ds_EOM_stCmbTdOff: data-element=P_EOM_stCmbTdOff.EOM_stCmbTdOff
        ds_Veh_bHeatWaPmpReq: data-element=P_Veh_bHeatWaPmpReq.Veh_bHeatWaPmpReq
        ds_VSCtl_stDVSRegExtd: data-element=P_VSCtl_stDVSRegExtd.VSCtl_stDVSRegExtd
        ds_Ext_tECTSp: data-element=P_Ext_tECTSp.Ext_tECTSp
        ds_CoVSCtl_tqIdcSIPTar: data-element=P_CoVSCtl_tqIdcSIPTar.CoVSCtl_tqIdcSIPTar
        ds_Ext_rCorSoCHyb: data-element=P_Ext_rCorSoCHyb.Ext_rCorSoCHyb
        ds_VSSCtzMgt_bUcapSerAcvTest: data-element=P_VSSCtzMgt_bUcapSerAcvTest.VSSCtzMgt_bUcapSerAcvTest
        ds_WaTEst_rErrTCo: data-element=P_WaTEst_rErrTCo.WaTEst_rErrTCo
        ds_PtLim_tqWhlPTMinNotCtla: data-element=P_PtLim_tqWhlPTMinNotCtla.PtLim_tqWhlPTMinNotCtla
        ds_CoReqVeh_bEngASERstrtReq: data-element=P_CoReqVeh_bEngASERstrtReq.CoReqVeh_bEngASERstrtReq
        ds_CoReqDmpr_bEngRStrtReq: data-element=P_CoReqDmpr_bEngRStrtReq.CoReqDmpr_bEngRStrtReq
        ds_VSCtl_tiCfmSdwnDVSRegReq: data-element=P_VSCtl_tiCfmSdwnDVSRegReq.VSCtl_tiCfmSdwnDVSRegReq
        ds_InjSP_mfFuPoI1Req: data-element=P_InjSP_mfFuPoI1Req.InjSP_mfFuPoI1Req
        ds_Ext_tUsPFlt: data-element=P_Ext_tUsPFlt.Ext_tUsPFlt
        ds_Brk_tqWhlBrkReq: data-element=P_Brk_tqWhlBrkReq.Brk_tqWhlBrkReq
        ds_ExM_cppExFlex: data-element=P_ExM_cppExFlex.ExM_cppExFlex
        ds_Ext_facRhoFu: data-element=P_Ext_facRhoFu.Ext_facRhoFu
        ds_AfuA_bFlexAdpAcv: data-element=P_AfuA_bFlexAdpAcv.AfuA_bFlexAdpAcv
        ds_EngLim_tqIdcEngLim: data-element=P_EngLim_tqIdcEngLim.EngLim_tqIdcEngLim
        ds_VSSCtzMgt_bAcvElCnsReq: data-element=P_VSSCtzMgt_bAcvElCnsReq.VSSCtzMgt_bAcvElCnsReq
        ds_CoVSCtl_tqSIPTar: data-element=P_CoVSCtl_tqSIPTar.CoVSCtl_tqSIPTar
        ds_EngM_dstExVlvClrCor: data-element=P_EngM_dstExVlvClrCor.EngM_dstExVlvClrCor
        ds_Afts_bRst_stDeacVSMaxReq1: data-element=P_Afts_bRst_stDeacVSMaxReq1.Afts_bRst_stDeacVSMaxReq1
        ds_EGRVlv_bAcvClsEGRReq: data-element=P_EGRVlv_bAcvClsEGRReq.EGRVlv_bAcvClsEGRReq
        ds_EGRVlv_bClnEGRFoul: data-element=P_EGRVlv_bClnEGRFoul.EGRVlv_bClnEGRFoul
        ds_EGRVlv_rOp: data-element=P_EGRVlv_rOp.EGRVlv_rOp
        ds_EngLim_tqCkEfcStatLimExt: data-element=P_EngLim_tqCkEfcStatLimExt.EngLim_tqCkEfcStatLimExt
        ds_Ext_stPwrLimCf: data-element=P_Ext_stPwrLimCf.Ext_stPwrLimCf
        ds_ExM_molMassInWoutRgGas: data-element=P_ExM_molMassInWoutRgGas.ExM_molMassInWoutRgGas
        ds_VSSCtzMgt_rUcapSoHTreat: data-element=P_VSSCtzMgt_rUcapSoHTreat.VSSCtzMgt_rUcapSoHTreat
        ds_IgSys_agIgMinThermoFlex: data-element=P_IgSys_agIgMinThermoFlex.IgSys_agIgMinThermoFlex
        ds_EngM_tUsTrbEstimFil: data-element=P_EngM_tUsTrbEstimFil.EngM_tUsTrbEstimFil
        ds_WaTEst_tMtlEngEstim: data-element=P_WaTEst_tMtlEngEstim.WaTEst_tMtlEngEstim
        ds_GlwCtl_bEngRunAuth: data-element=P_GlwCtl_bEngRunAuth.GlwCtl_bEngRunAuth
        ds_ElSysCo_bOpFSFReq: data-element=P_ElSysCo_bOpFSFReq.ElSysCo_bOpFSFReq
        ds_VSSCtzMgt_stUcapDchaRslt: data-element=P_VSSCtzMgt_stUcapDchaRslt.VSSCtzMgt_stUcapDchaRslt
        ds_CoEmSTT_bAuthBoost: data-element=P_CoEmSTT_bAuthBoost.CoEmSTT_bAuthBoost
        ds_PtLim_tqWhlThPTPotMin: data-element=P_PtLim_tqWhlThPTPotMin.PtLim_tqWhlThPTPotMin
        ds_CoReqCha_bEngASERstrtReq: data-element=P_CoReqCha_bEngASERstrtReq.CoReqCha_bEngASERstrtReq
        ds_TqSys_bAcceDetAOSExt: data-element=P_TqSys_bAcceDetAOSExt.TqSys_bAcceDetAOSExt
        ds_ExM_tExGas: data-element=P_ExM_tExGas.ExM_tExGas
        ds_IgSys_prm_facFlex: data-element=P_IgSys_prm_facFlex.IgSys_prm_facFlex
        ds_Afts_bRst_stDeacVSLimReq1: data-element=P_Afts_bRst_stDeacVSLimReq1.Afts_bRst_stDeacVSLimReq1
        ds_TqDem_tqWhlPTPreCoVSCtlReq: data-element=P_TqDem_tqWhlPTPreCoVSCtlReq.TqDem_tqWhlPTPreCoVSCtlReq
        ds_CoVlv_rOpBypCoVlvMes: data-element=P_CoVlv_rOpBypCoVlvMes.CoVlv_rOpBypCoVlvMes
        ds_IgSys_agIgOptmFlex: data-element=P_IgSys_agIgOptmFlex.IgSys_agIgOptmFlex
        ds_PtLim_tqWhlPTMaxNotCtla: data-element=P_PtLim_tqWhlPTMaxNotCtla.PtLim_tqWhlPTMaxNotCtla
        ds_Afts_bRst_stDeacVSMaxReq2: data-element=P_Afts_bRst_stDeacVSMaxReq2.Afts_bRst_stDeacVSMaxReq2
        ds_Ext_bGslEngPrepReq: data-element=P_Ext_bGslEngPrepReq.Ext_bGslEngPrepReq
        ds_CoCha_tqEfcReqExt: data-element=P_CoCha_tqEfcReqExt.CoCha_tqEfcReqExt
        ds_VehEst_bCtlTqWhlPT: data-element=P_VehEst_bCtlTqWhlPT.VehEst_bCtlTqWhlPT
        ds_RvAltMgt_tqRvAltGenModEstim: data-element=P_RvAltMgt_tqRvAltGenModEstim.RvAltMgt_tqRvAltGenModEstim
        ds_TqSys_tqAOSCVC: data-element=P_TqSys_tqAOSCVC.TqSys_tqAOSCVC
        ds_VSSCtzMgt_stVSSCtzAcvSt: data-element=P_VSSCtzMgt_stVSSCtzAcvSt.VSSCtzMgt_stVSSCtzAcvSt
        ds_TqSys_tqCkIdl: data-element=P_TqSys_tqCkIdl.TqSys_tqCkIdl
        ds_Ext_bDetLoWhlGrip: data-element=P_Ext_bDetLoWhlGrip.Ext_bDetLoWhlGrip
        ds_Tra_stVehDirEstim: data-element=P_Tra_stVehDirEstim.Tra_stVehDirEstim
        ds_ExM_facIgCorFlex: data-element=P_ExM_facIgCorFlex.ExM_facIgCorFlex
        ds_Tra_bVoltAltBoostReqGBx: data-element=P_Tra_bVoltAltBoostReqGBx.Tra_bVoltAltBoostReqGBx
        ds_ExM_tExFlex: data-element=P_ExM_tExFlex.ExM_tExFlex
        ds_Ext_bEspVehVld: data-element=P_Ext_bEspVehVld.Ext_bEspVehVld
        ds_VSSCtzMgt_uUcapMes: data-element=P_VSSCtzMgt_uUcapMes.VSSCtzMgt_uUcapMes
        ds_TqDem_tqWhlPTDrvMinReqRaw: data-element=P_TqDem_tqWhlPTDrvMinReqRaw.TqDem_tqWhlPTDrvMinReqRaw
        ds_Ext_bAdFanAct: data-element=P_Ext_bAdFanAct.Ext_bAdFanAct
        ds_TqDem_tqWhlPTPreCoVSCMinReq: data-element=P_TqDem_tqWhlPTPreCoVSCMinReq.TqDem_tqWhlPTPreCoVSCMinReq
        ds_ExM_facLamCorFlex: data-element=P_ExM_facLamCorFlex.ExM_facLamCorFlex
        ds_RvAltMgt_tRvAltStatEstim: data-element=P_RvAltMgt_tRvAltStatEstim.RvAltMgt_tRvAltStatEstim
        ds_TqSys_tqThdPha3Ext: data-element=P_TqSys_tqThdPha3Ext.TqSys_tqThdPha3Ext
        ds_Brk_bBrkAuto: data-element=P_Brk_bBrkAuto.Brk_bBrkAuto
        ds_ExM_pMes: data-element=P_ExM_pMes.ExM_pMes
        ds_RvAltMgt_bStopStrtWarn: data-element=P_RvAltMgt_bStopStrtWarn.RvAltMgt_bStopStrtWarn
        ds_Ext_bTqAltEstimElSys: data-element=P_Ext_bTqAltEstimElSys.Ext_bTqAltEstimElSys
        ds_Blby_bIncIdlSpd: data-element=P_Blby_bIncIdlSpd.Blby_bIncIdlSpd
        ds_TqSys_bInhBrio: data-element=P_TqSys_bInhBrio.TqSys_bInhBrio
        ds_VSCtl_rCtlTqWhlPTPotDVSReg: data-element=P_VSCtl_rCtlTqWhlPTPotDVSReg.VSCtl_rCtlTqWhlPTPotDVSReg
        ds_IgSys_agIgMinThermoGas: data-element=P_IgSys_agIgMinThermoGas.IgSys_agIgMinThermoGas
        ds_Ext_bAvlTqWhlPT_no2: data-element=P_Ext_bAvlTqWhlPT_no2.Ext_bAvlTqWhlPT_no2
        ds_VehEst_tqWhlPTRealEstim: data-element=P_VehEst_tqWhlPTRealEstim.VehEst_tqWhlPTRealEstim
        ds_CoVSCtl_rAccPEngExt: data-element=P_CoVSCtl_rAccPEngExt.CoVSCtl_rAccPEngExt
        ds_EngM_mfEgEstim: data-element=P_EngM_mfEgEstim.EngM_mfEgEstim
        ds_EOM_stCmbMod: data-element=P_EOM_stCmbMod.EOM_stCmbMod
        ds_CoEmSTT_bEngASERstrtReq: data-element=P_CoEmSTT_bEngASERstrtReq.CoEmSTT_bEngASERstrtReq
        ds_Afts_bRstCylBlockDmgReq: data-element=P_Afts_bRstCylBlockDmgReq.Afts_bRstCylBlockDmgReq
        ds_Ext_bDiDrivFilReq: data-element=P_Ext_bDiDrivFilReq.Ext_bDiDrivFilReq
        ds_CoPt_bInhEngStopProtManClu: data-element=P_CoPt_bInhEngStopProtManClu.CoPt_bInhEngStopProtManClu
        ds_IgSys_agIgCmbModOfsMinThermo: data-element=P_IgSys_agIgCmbModOfsMinThermo.IgSys_agIgCmbModOfsMinThermo
        ds_Ext_bAvrFrntWhlVld: data-element=P_Ext_bAvrFrntWhlVld.Ext_bAvrFrntWhlVld
        ds_CoPt_nTarIdlCVC: data-element=P_CoPt_nTarIdlCVC.CoPt_nTarIdlCVC
        ds_IgSys_agIgCylPresMaxFlex: data-element=P_IgSys_agIgCylPresMaxFlex.IgSys_agIgCylPresMaxFlex
        ds_ExM_facLamCorGas: data-element=P_ExM_facLamCorGas.ExM_facLamCorGas
        ds_TqSys_bInhTqDemSptMod: data-element=P_TqSys_bInhTqDemSptMod.TqSys_bInhTqDemSptMod
        ds_GlwCtl_bEngRunReq: data-element=P_GlwCtl_bEngRunReq.GlwCtl_bEngRunReq
        ds_Ext_bTyreWarn: data-element=P_Ext_bTyreWarn.Ext_bTyreWarn
        ds_VSSCtzMgt_tUcapMes: data-element=P_VSSCtzMgt_tUcapMes.VSSCtzMgt_tUcapMes
        ds_TqCha_tqAirTqIncReqExt: data-element=P_TqCha_tqAirTqIncReqExt.TqCha_tqAirTqIncReqExt
        ds_VSCtl_stCtl_aVehPotDVSReg: data-element=P_VSCtl_stCtl_aVehPotDVSReg.VSCtl_stCtl_aVehPotDVSReg
        ds_EngM_facCorSlopEfc: data-element=P_EngM_facCorSlopEfc.EngM_facCorSlopEfc
        ds_TqSys_stDrivFilPhaExt: data-element=P_TqSys_stDrivFilPhaExt.TqSys_stDrivFilPhaExt
        ds_EngM_dstInVlvClrCor: data-element=P_EngM_dstInVlvClrCor.EngM_dstInVlvClrCor
        ds_Blby_bCfHiMfBlby: data-element=P_Blby_bCfHiMfBlby.Blby_bCfHiMfBlby
        ds_EOM_idxBas2InjCur: data-element=P_EOM_idxBas2InjCur.EOM_idxBas2InjCur
        ds_InjSP_mfFuPoI2Req: data-element=P_InjSP_mfFuPoI2Req.InjSP_mfFuPoI2Req
        ds_Ext_bAcvGasMod: data-element=P_Ext_bAcvGasMod.Ext_bAcvGasMod
        ds_CoPtFH_bEngRunReq: data-element=P_CoPtFH_bEngRunReq.CoPtFH_bEngRunReq
        ds_TqSys_tqCkDeceIniExt: data-element=P_TqSys_tqCkDeceIniExt.TqSys_tqCkDeceIniExt
        ds_RvAltMgt_uRvAltMes: data-element=P_RvAltMgt_uRvAltMes.RvAltMgt_uRvAltMes
        ds_Stg_tSysStrWhl: data-element=P_Stg_tSysStrWhl.Stg_tSysStrWhl
        ds_PtLim_tqWhlPTMaxCtla: data-element=P_PtLim_tqWhlPTMaxCtla.PtLim_tqWhlPTMaxCtla
        ds_ExM_tEgMes: data-element=P_ExM_tEgMes.ExM_tEgMes
        ds_PARM_bEngRstrtAutnAvl: data-element=P_PARM_bEngRstrtAutnAvl.PARM_bEngRstrtAutnAvl
        ds_VSCtl_stCtl_aVehDVSReg: data-element=P_VSCtl_stCtl_aVehDVSReg.VSCtl_stCtl_aVehDVSReg
        ds_Ext_bAvlTqWhlPT_no3: data-element=P_Ext_bAvlTqWhlPT_no3.Ext_bAvlTqWhlPT_no3
        ds_TqSys_facReqExhTempProt: data-element=P_TqSys_facReqExhTempProt.TqSys_facReqExhTempProt
        ds_CoReqCha_bEngStallAuth: data-element=P_CoReqCha_bEngStallAuth.CoReqCha_bEngStallAuth
        ds_Ext_bAvlTqWhlPT_no1: data-element=P_Ext_bAvlTqWhlPT_no1.Ext_bAvlTqWhlPT_no1
        ds_Afts_bRst_stDeacVSLimReq2: data-element=P_Afts_bRst_stDeacVSLimReq2.Afts_bRst_stDeacVSLimReq2
        ds_IgSys_agIgMinCmbFlex: data-element=P_IgSys_agIgMinCmbFlex.IgSys_agIgMinCmbFlex
        ds_TqSys_tqCkIdlMin: data-element=P_TqSys_tqCkIdlMin.TqSys_tqCkIdlMin
        ds_Tra_bEngCrawlAuth: data-element=P_Tra_bEngCrawlAuth.Tra_bEngCrawlAuth
        ds_CoPtASE_bAltStrtTypASEReq: data-element=P_CoPtASE_bAltStrtTypASEReq.CoPtASE_bAltStrtTypASEReq
        ds_RvAltMgt_nRvAltMv: data-element=P_RvAltMgt_nRvAltMv.RvAltMgt_nRvAltMv
        ds_CoPtUH_bEngAsiReqExt: data-element=P_CoPtUH_bEngAsiReqExt.CoPtUH_bEngAsiReqExt
        ds_EGRVlv_stEGRMod: data-element=P_EGRVlv_stEGRMod.EGRVlv_stEGRMod
        ds_TqDem_tqWhlPTDrvMaxReq: data-element=P_TqDem_tqWhlPTDrvMaxReq.TqDem_tqWhlPTDrvMaxReq
        ds_TqCmp_pwrACAuxLoss: data-element=P_TqCmp_pwrACAuxLoss.TqCmp_pwrACAuxLoss
        ds_RvAltMgt_tqRvAltGenModMv: data-element=P_RvAltMgt_tqRvAltGenModMv.RvAltMgt_tqRvAltGenModMv
        ds_Blby_bDecPfu: data-element=P_Blby_bDecPfu.Blby_bDecPfu
        ds_Brk_tqWhlBrkEstim: data-element=P_Brk_tqWhlBrkEstim.Brk_tqWhlBrkEstim
        ds_VSCtl_aVehDVSRegReq: data-element=P_VSCtl_aVehDVSRegReq.VSCtl_aVehDVSRegReq
        ds_VSSCtzMgt_stVSSCtzFctLvl: data-element=P_VSSCtzMgt_stVSSCtzFctLvl.VSSCtzMgt_stVSSCtzFctLvl
        ds_PredRstrt_tiMax2TDC: data-element=P_PredRstrt_tiMax2TDC.PredRstrt_tiMax2TDC
        ds_Ext_bFrntLeftWhlVehVld: data-element=P_Ext_bFrntLeftWhlVehVld.Ext_bFrntLeftWhlVehVld
        ds_Afts_bRstTrbCaseDmgReq: data-element=P_Afts_bRstTrbCaseDmgReq.Afts_bRstTrbCaseDmgReq
        ds_Afts_bRst_stDeacVSRegReq2: data-element=P_Afts_bRst_stDeacVSRegReq2.Afts_bRst_stDeacVSRegReq2
        ds_ExM_molMassInWoutRgFlex: data-element=P_ExM_molMassInWoutRgFlex.ExM_molMassInWoutRgFlex
        ds_Afts_bRstCylHdDmgReq: data-element=P_Afts_bRstCylHdDmgReq.Afts_bRstCylHdDmgReq
        ds_EngLim_tqIdcLimMin: data-element=P_EngLim_tqIdcLimMin.EngLim_tqIdcLimMin
        ds_ExM_prm_facGas: data-element=P_ExM_prm_facGas.ExM_prm_facGas
        ds_ExM_molMassExFlex: data-element=P_ExM_molMassExFlex.ExM_molMassExFlex
        ds_Ext_stUcapChSpElMgt: data-element=P_Ext_stUcapChSpElMgt.Ext_stUcapChSpElMgt
        ds_TqSys_nOfsLauchIdlTakeOff: data-element=P_TqSys_nOfsLauchIdlTakeOff.TqSys_nOfsLauchIdlTakeOff
        ds_PFlt_bPFltRgnSrvReq: data-element=P_PFlt_bPFltRgnSrvReq.PFlt_bPFltRgnSrvReq
        ds_EGRVlv_rOpEGRReq: data-element=P_EGRVlv_rOpEGRReq.EGRVlv_rOpEGRReq
        ds_TqSys_nTarDynIdl: data-element=P_TqSys_nTarDynIdl.TqSys_nTarDynIdl
        ds_Afts_bRst_stDeacVSRegReq1: data-element=P_Afts_bRst_stDeacVSRegReq1.Afts_bRst_stDeacVSRegReq1
        ds_RvAltMgt_bIdcVldCurGenMod: data-element=P_RvAltMgt_bIdcVldCurGenMod.RvAltMgt_bIdcVldCurGenMod
        ds_TqSys_facReqFuelRunDry: data-element=P_TqSys_facReqFuelRunDry.TqSys_facReqFuelRunDry
        ds_TqSys_tqCkEfcFilExt: data-element=P_TqSys_tqCkEfcFilExt.TqSys_tqCkEfcFilExt
        ds_TqCmp_bOpFSFReq_tAir: data-element=P_TqCmp_bOpFSFReq_tAir.TqCmp_bOpFSFReq_tAir
        ds_TqSys_noCylCutAuthExt: data-element=P_TqSys_noCylCutAuthExt.TqSys_noCylCutAuthExt
        ds_VehEst_spdVehCrit: data-element=P_VehEst_spdVehCrit.VehEst_spdVehCrit
        ds_TqDem_tqWhlPTDrvReq: data-element=P_TqDem_tqWhlPTDrvReq.TqDem_tqWhlPTDrvReq
        ds_CoPt_facAntiJerkExt: data-element=P_CoPt_facAntiJerkExt.CoPt_facAntiJerkExt
        ds_ExM_tExFlexOfs: data-element=P_ExM_tExFlexOfs.ExM_tExFlexOfs
        ds_VehEst_tqWhlPTReq: data-element=P_VehEst_tqWhlPTReq.VehEst_tqWhlPTReq
        ds_TPM_rAirLdReqGas: data-element=P_TPM_rAirLdReqGas.TPM_rAirLdReqGas
        ds_EngLim_tqIdcColdSmkRaw: data-element=P_EngLim_tqIdcColdSmkRaw.EngLim_tqIdcColdSmkRaw
        ds_TqLimUH_bAcvUnBlsEng: data-element=P_TqLimUH_bAcvUnBlsEng.TqLimUH_bAcvUnBlsEng
        ds_TqCha_tqAirTqDecReqExt: data-element=P_TqCha_tqAirTqDecReqExt.TqCha_tqAirTqDecReqExt
        ds_RvAltMgt_stRvAltRstrtFbCmd: data-element=P_RvAltMgt_stRvAltRstrtFbCmd.RvAltMgt_stRvAltRstrtFbCmd
        ds_VSCtl_stVSReg: data-element=P_VSCtl_stVSReg.VSCtl_stVSReg
        ds_CoCha_tqEfcAirReqExt: data-element=P_CoCha_tqEfcAirReqExt.CoCha_tqEfcAirReqExt
        ds_Afts_bSpcFactOnDeacInh: data-element=P_Afts_bSpcFactOnDeacInh.Afts_bSpcFactOnDeacInh
        ds_AfuA_rFlex: data-element=P_AfuA_rFlex.AfuA_rFlex
        ds_CoPtASE_bEngStrtTypASEReq: data-element=P_CoPtASE_bEngStrtTypASEReq.CoPtASE_bEngStrtTypASEReq
        ds_TqDem_tqWhlPTPreCoVSCMaxReq: data-element=P_TqDem_tqWhlPTPreCoVSCMaxReq.TqDem_tqWhlPTPreCoVSCMaxReq
        ds_VSCtl_stVSLim: data-element=P_VSCtl_stVSLim.VSCtl_stVSLim
        ds_RvAltMgt_iRvAltGenModEstim: data-element=P_RvAltMgt_iRvAltGenModEstim.RvAltMgt_iRvAltGenModEstim
        ds_Afts_bUcapChgIdc: data-element=P_Afts_bUcapChgIdc.Afts_bUcapChgIdc
        ds_EngLim_tqIdcEngProt: data-element=P_EngLim_tqIdcEngProt.EngLim_tqIdcEngProt
        ds_PtLim_tqWhlPTPotMaxCtla_no2: data-element=P_PtLim_tqWhlPTPotMaxCtla_no2.PtLim_tqWhlPTPotMaxCtla_no2
        ds_CoCha_bInhEGRExt: data-element=P_CoCha_bInhEGRExt.CoCha_bInhEGRExt
        ds_EOM_idxBas1InjCur: data-element=P_EOM_idxBas1InjCur.EOM_idxBas1InjCur
        ds_CoPt_bDeacCllExt: data-element=P_CoPt_bDeacCllExt.CoPt_bDeacCllExt
        ds_Afts_bVSSCtzActrTestCmd: data-element=P_Afts_bVSSCtzActrTestCmd.Afts_bVSSCtzActrTestCmd
        ds_ExM_cppIngGas: data-element=P_ExM_cppIngGas.ExM_cppIngGas
        ds_RvAltMgt_stRvAltModReq: data-element=P_RvAltMgt_stRvAltModReq.RvAltMgt_stRvAltModReq
        ds_ExM_molMassExGas: data-element=P_ExM_molMassExGas.ExM_molMassExGas
        ds_TqSys_tqIncCllExt: data-element=P_TqSys_tqIncCllExt.TqSys_tqIncCllExt
        ds_Ext_stDirMoveVeh: data-element=P_Ext_stDirMoveVeh.Ext_stDirMoveVeh
        ds_ElSysCo_rSpdFanReq: data-element=P_ElSysCo_rSpdFanReq.ElSysCo_rSpdFanReq
        ds_EngM_facCorOfsEfc: data-element=P_EngM_facCorOfsEfc.EngM_facCorOfsEfc
        ds_VSCtl_stVSMax: data-element=P_VSCtl_stVSMax.VSCtl_stVSMax
        ds_PFlt_bPFltRgnReq: data-element=P_PFlt_bPFltRgnReq.PFlt_bPFltRgnReq
        ds_AfuA_rEthWiExct: data-element=P_AfuA_rEthWiExct.AfuA_rEthWiExct
        ds_TqSys_stStrtEngTyp: data-element=P_TqSys_stStrtEngTyp.TqSys_stStrtEngTyp
        ds_CoReqVeh_bEngStallAuth: data-element=P_CoReqVeh_bEngStallAuth.CoReqVeh_bEngStallAuth
        ds_IgSys_agIgMinCmbGas: data-element=P_IgSys_agIgMinCmbGas.IgSys_agIgMinCmbGas
        ds_Tra_bSpdVehLoDet: data-element=P_Tra_bSpdVehLoDet.Tra_bSpdVehLoDet
        ds_TqSys_nOfsFFL: data-element=P_TqSys_nOfsFFL.TqSys_nOfsFFL
        ds_OilTqCf_bPresOilReqCf: data-element=P_OilTqCf_bPresOilReqCf.OilTqCf_bPresOilReqCf
        ds_EngLim_tqIdcSmkLim: data-element=P_EngLim_tqIdcSmkLim.EngLim_tqIdcSmkLim
        ds_IgSys_agIgOptmGas: data-element=P_IgSys_agIgOptmGas.IgSys_agIgOptmGas
        ds_RvAltMgt_tqRstrtMaxEstim: data-element=P_RvAltMgt_tqRstrtMaxEstim.RvAltMgt_tqRstrtMaxEstim
        ds_Tra_bInhAC: data-element=P_Tra_bInhAC.Tra_bInhAC
        ds_VehEst_rTqWhlPTRe: data-element=P_VehEst_rTqWhlPTRe.VehEst_rTqWhlPTRe
        ds_CoReqDmpr_stEngStopAuth: data-element=P_CoReqDmpr_stEngStopAuth.CoReqDmpr_stEngStopAuth
        ds_CoVlv_rOpHeatCoVlvMes: data-element=P_CoVlv_rOpHeatCoVlvMes.CoVlv_rOpHeatCoVlvMes
        ds_ExM_rGas: data-element=P_ExM_rGas.ExM_rGas
        ds_FARSp_rDeltaMixtStiTWCSp: data-element=P_FARSp_rDeltaMixtStiTWCSp.FARSp_rDeltaMixtStiTWCSp
        ds_MCT_tqFrntMchEstim: data-element=P_MCT_tqFrntMchEstim.MCT_tqFrntMchEstim
        ds_EOM_facItpolCur: data-element=P_EOM_facItpolCur.EOM_facItpolCur
        ds_RvAltMgt_nRvAltMes: data-element=P_RvAltMgt_nRvAltMes.RvAltMgt_nRvAltMes
        ds_AirSys_rOpEGRCoBypReq: data-element=P_AirSys_rOpEGRCoBypReq.AirSys_rOpEGRCoBypReq
        ds_TqSys_bAcceClrCrossAOSExt: data-element=P_TqSys_bAcceClrCrossAOSExt.TqSys_bAcceClrCrossAOSExt
        ds_IgSys_agIgMaxFlex: data-element=P_IgSys_agIgMaxFlex.IgSys_agIgMaxFlex
        ds_VSSCtzMgt_resVSSCtzEstim: data-element=P_VSSCtzMgt_resVSSCtzEstim.VSSCtzMgt_resVSSCtzEstim
        ds_AfuA_rEthStoich: data-element=P_AfuA_rEthStoich.AfuA_rEthStoich
        ds_CoPt_tqFfNRegBuf: data-element=P_CoPt_tqFfNRegBuf.CoPt_tqFfNRegBuf
        ds_CoPt_bAcvTqNCordBuf: data-element=P_CoPt_bAcvTqNCordBuf.CoPt_bAcvTqNCordBuf
        ds_TqAdp_bFrzAdpACAuxOn: data-element=P_TqAdp_bFrzAdpACAuxOn.TqAdp_bFrzAdpACAuxOn
        ds_CoPt_tqEfcAirCordLimExtTqGBx: data-element=P_CoPt_tqEfcAirCordLimExtTqGBx.CoPt_tqEfcAirCordLimExtTqGBx
        ds_CoReqDamp_bEngStallAuth: data-element=P_CoReqDamp_bEngStallAuth.CoReqDamp_bEngStallAuth
        ds_TqSys_bDeceDetAOSExt: data-element=P_TqSys_bDeceDetAOSExt.TqSys_bDeceDetAOSExt
        ds_ExM_facIgCorGas: data-element=P_ExM_facIgCorGas.ExM_facIgCorGas
        ds_CoPtFH_bEngStopReq: data-element=P_CoPtFH_bEngStopReq.CoPtFH_bEngStopReq
        ds_PtLim_tqWhlPTMinCtla: data-element=P_PtLim_tqWhlPTMinCtla.PtLim_tqWhlPTMinCtla
        ds_EngLim_tqIdcFLdUnlim: data-element=P_EngLim_tqIdcFLdUnlim.EngLim_tqIdcFLdUnlim
        ds_TqSys_tqCkEfcAirFilExt: data-element=P_TqSys_tqCkEfcAirFilExt.TqSys_tqCkEfcAirFilExt
        ds_Ext_tVSS: data-element=P_Ext_tVSS.Ext_tVSS
        ds_TqSys_tiTranCllExt: data-element=P_TqSys_tiTranCllExt.TqSys_tiTranCllExt
        ds_TqSys_bAcvCllExt: data-element=P_TqSys_bAcvCllExt.TqSys_bAcvCllExt
        ds_TqEst_tqIdcStrt: data-element=P_TqEst_tqIdcStrt.TqEst_tqIdcStrt
        ds_AfuA_rEthWoutExct: data-element=P_AfuA_rEthWoutExct.AfuA_rEthWoutExct
        ds_Tra_bNRegTyp: data-element=P_Tra_bNRegTyp.Tra_bNRegTyp
        ds_VSCtl_tiCfmSupDVSRegReq: data-element=P_VSCtl_tiCfmSupDVSRegReq.VSCtl_tiCfmSupDVSRegReq
        ds_Ext_bFrntRightWhlVehVld: data-element=P_Ext_bFrntRightWhlVehVld.Ext_bFrntRightWhlVehVld
        ds_TqSys_bIdlAcv: data-element=P_TqSys_bIdlAcv.TqSys_bIdlAcv
        ds_PtLim_tqWhlPTPotMinCtla: data-element=P_PtLim_tqWhlPTPotMinCtla.PtLim_tqWhlPTPotMinCtla
        ds_EngLim_tqIdcSfty: data-element=P_EngLim_tqIdcSfty.EngLim_tqIdcSfty
        ds_Veh_stHeatCoFlowReq: data-element=P_Veh_stHeatCoFlowReq.Veh_stHeatCoFlowReq
        ds_OilTqCf_facNum: data-element=P_OilTqCf_facNum.OilTqCf_facNum
        ds_Ext_stSpdFanPFltReq: data-element=P_Ext_stSpdFanPFltReq.Ext_stSpdFanPFltReq
        ds_CoPt_tqEfcCordLimExt_tqGBx: data-element=P_CoPt_tqEfcCordLimExt_tqGBx.CoPt_tqEfcCordLimExt_tqGBx
        ds_VSCtl_aVehPotDVSRegReq: data-element=P_VSCtl_aVehPotDVSRegReq.VSCtl_aVehPotDVSRegReq
        ds_OAM_rOilDil: data-element=P_OAM_rOilDil.OAM_rOilDil
        ds_TqEst_tqIdcEstim: data-element=P_TqEst_tqIdcEstim.TqEst_tqIdcEstim
        ds_ExM_cppIngFlex: data-element=P_ExM_cppIngFlex.ExM_cppIngFlex
        ds_EOM_stEngModReq: data-element=P_EOM_stEngModReq.EOM_stEngModReq
        ds_EngReqH_bEngStallAuth: data-element=P_EngReqH_bEngStallAuth.EngReqH_bEngStallAuth
        ds_EngM_mfDsEGRCoEstim: data-element=P_EngM_mfDsEGRCoEstim.EngM_mfDsEGRCoEstim
        ds_ExM_prm_facFlex: data-element=P_ExM_prm_facFlex.ExM_prm_facFlex
        ds_SftyMgt_bDeacIrvVSLim: data-element=P_SftyMgt_bDeacIrvVSLim.SftyMgt_bDeacIrvVSLim
        ds_InjSys_tqIdcMinFeas: data-element=P_InjSys_tqIdcMinFeas.InjSys_tqIdcMinFeas
        ds_CoSync_bAgEsCfm: data-element=P_CoSync_bAgEsCfm.CoSync_bAgEsCfm
        ds_PtLim_tqWhlThPTMin: data-element=P_PtLim_tqWhlThPTMin.PtLim_tqWhlThPTMin
        ds_CoPtUH_bEngAsiReq: data-element=P_CoPtUH_bEngAsiReq.CoPtUH_bEngAsiReq
  swc implementation IMP_EBStub: programming-language=C, behavior=IB_EBStub
    code-descriptors:
      code CodeDescriptor: type=SRC
        7 x xfile:
          EBStub_calibrations_h: url=EBStub_calibrations.h
          EBSTUB_Version_c: url=EBSTUB_Version.c
          EBSTUB_Version_h: url=EBSTUB_Version.h
          EBSTUB_MemMap_h: url=EBSTUB_MemMap.h
          RE_EBStub_001_MSE_h: url=RE_EBStub_001_MSE.h
          EBStub_calibrations_c: url=EBStub_calibrations.c
          RE_EBStub_001_MSE_c: url=RE_EBStub_001_MSE.c
